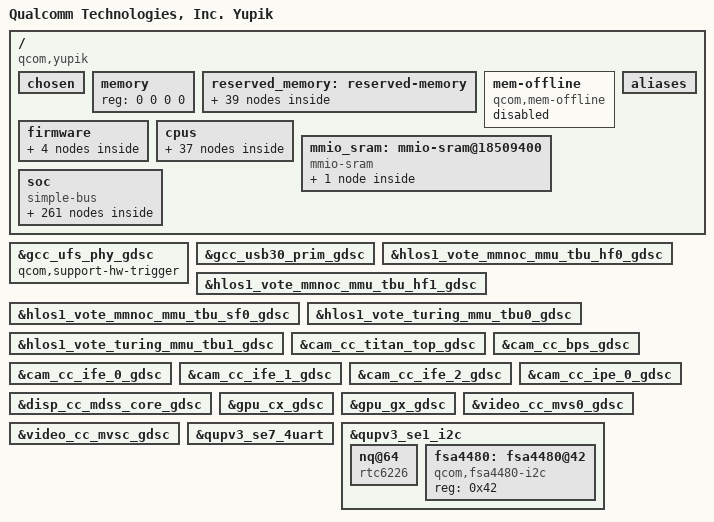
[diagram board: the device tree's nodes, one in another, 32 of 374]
// SPDX-License-Identifier: BSD-3-Clause
/*
 * Copyright (c) Qualcomm Technologies, Inc. and/or its subsidiaries.
 */

#include <dt-bindings/clock/qcom,aop-qmp.h>
#include <dt-bindings/clock/qcom,camcc-sc7280.h>
#include <dt-bindings/clock/qcom,dispcc-sc7280.h>
#include <dt-bindings/clock/qcom,gcc-sc7280.h>
#include <dt-bindings/clock/qcom,gpucc-sc7280.h>
#include <dt-bindings/clock/qcom,rpmh.h>
#include <dt-bindings/clock/qcom,videocc-sc7280.h>
#include <dt-bindings/interconnect/qcom,icc.h>
#include <dt-bindings/interconnect/qcom,yupik.h>
#include <dt-bindings/interrupt-controller/arm-gic.h>
#include <dt-bindings/soc/qcom,ipcc.h>
#include <dt-bindings/soc/qcom,dcc_v2.h>
#include <dt-bindings/soc/qcom,rpmh-rsc.h>
#include <dt-bindings/spmi/spmi.h>
#include <dt-bindings/gpio/gpio.h>
#include <dt-bindings/regulator/qcom,rpmh-regulator-levels.h>

/ {
	model = "Qualcomm Technologies, Inc. Yupik";
	compatible = "qcom,yupik";
	qcom,msm-id = <475 0x10000>, <515 0x10000>;
	interrupt-parent = <&intc>;

	#address-cells = <2>;
	#size-cells = <2>;

	chosen: chosen {
		bootargs = "loglevel=6 log_buf_len=512K earlycon=qcom_geni,0x994000 rcupdate.rcu_expedited=1  printk.console_no_auto_verbose=1 rcu_nocbs=0-7 kpti=0 cpufreq.default_governor=performance printk.devkmsg=on pcie_ports=compat fw_devlink.strict=1 android_arch_task_struct_size=512 androidboot.usbcontroller=a600000.dwc3";
		stdout-path = "/soc/qcom,qupv3_0_geni_se@9c0000/qcom,qup_uart@994000:115200n8";
	};

	memory { device_type = "memory"; reg = <0 0 0 0>; };

	reserved_memory: reserved-memory { };

	mem-offline {
		compatible = "qcom,mem-offline";
		offline-sizes = <0x1 0x40000000 0x0 0x40000000>,
			<0x1 0xc0000000 0x0 0x80000000>,
			<0x2 0xc0000000 0x1 0x40000000>;
		granule = <512>;
		mboxes = <&qmp_aop 0>;
		status = "disabled";
	};

	aliases: aliases {
		ufshc1 = &ufshc_mem; /* Embedded UFS Slot */
		mmc0 = &sdhc_1; /*SDC1 eMMC slot*/
		mmc1 = &sdhc_2; /* SDC2 SD card slot */
		serial0 = &qupv3_se5_2uart;
		hsuart0 = &qupv3_se7_4uart;
	};

	firmware: firmware {
		qcom_scm: qcom_scm { };
	};

	cpus {
		#address-cells = <2>;
		#size-cells = <0>;

		CPU0: cpu@0 {
			device_type = "cpu";
			compatible = "qcom,kryo";
			reg = <0x0 0x0>;
			enable-method = "psci";
			cpu-idle-states = <&LITTLE_CPU_SLEEP_0 &LITTLE_CPU_SLEEP_1>;
			power-domains = <&CPU_PD0>;
			power-domain-names = "psci";
			capacity-dmips-mhz = <1024>;
			dynamic-power-coefficient = <100>;
			qcom,freq-domain = <&cpufreq_hw 0 4>;
			next-level-cache = <&L2_0>;
			#cooling-cells = <2>;
			L2_0: l2-cache {
			      compatible = "cache";
			      cache-level = <2>;
			      next-level-cache = <&L3_0>;

				L3_0: l3-cache {
				      compatible = "cache";
				      cache-level = <3>;
				};
			};
		};

		CPU1: cpu@100 {
			device_type = "cpu";
			compatible = "qcom,kryo";
			reg = <0x0 0x100>;
			enable-method = "psci";
			cpu-idle-states = <&LITTLE_CPU_SLEEP_0 &LITTLE_CPU_SLEEP_1>;
			power-domains = <&CPU_PD1>;
			power-domain-names = "psci";
			capacity-dmips-mhz = <1024>;
			dynamic-power-coefficient = <100>;
			qcom,freq-domain = <&cpufreq_hw 0 4>;
			next-level-cache = <&L2_1>;
			#cooling-cells = <2>;
			L2_1: l2-cache {
			      compatible = "cache";
			      cache-level = <2>;
			      next-level-cache = <&L3_0>;
			};
		};

		CPU2: cpu@200 {
			device_type = "cpu";
			compatible = "qcom,kryo";
			reg = <0x0 0x200>;
			enable-method = "psci";
			cpu-idle-states = <&LITTLE_CPU_SLEEP_0 &LITTLE_CPU_SLEEP_1>;
			power-domains = <&CPU_PD2>;
			power-domain-names = "psci";
			capacity-dmips-mhz = <1024>;
			dynamic-power-coefficient = <100>;
			qcom,freq-domain = <&cpufreq_hw 0 4>;
			next-level-cache = <&L2_2>;
			#cooling-cells = <2>;
			L2_2: l2-cache {
			      compatible = "cache";
			      cache-level = <2>;
			      next-level-cache = <&L3_0>;
			};
		};

		CPU3: cpu@300 {
			device_type = "cpu";
			compatible = "qcom,kryo";
			reg = <0x0 0x300>;
			enable-method = "psci";
			cpu-idle-states = <&LITTLE_CPU_SLEEP_0 &LITTLE_CPU_SLEEP_1>;
			power-domains = <&CPU_PD3>;
			power-domain-names = "psci";
			capacity-dmips-mhz = <1024>;
			dynamic-power-coefficient = <100>;
			qcom,freq-domain = <&cpufreq_hw 0 4>;
			next-level-cache = <&L2_3>;
			#cooling-cells = <2>;
			L2_3: l2-cache {
			      compatible = "cache";
			      cache-level = <2>;
			      next-level-cache = <&L3_0>;
			};
		};

		CPU4: cpu@400 {
			device_type = "cpu";
			compatible = "qcom,kryo";
			reg = <0x0 0x400>;
			enable-method = "psci";
			cpu-idle-states = <&BIG_CPU_SLEEP_0 &BIG_CPU_SLEEP_1>;
			power-domains = <&CPU_PD4>;
			power-domain-names = "psci";
			capacity-dmips-mhz = <1946>;
			dynamic-power-coefficient = <520>;
			qcom,freq-domain = <&cpufreq_hw 1 4>;
			next-level-cache = <&L2_4>;
			#cooling-cells = <2>;
			L2_4: l2-cache {
			      compatible = "cache";
			      cache-level = <2>;
			      next-level-cache = <&L3_0>;
			};
		};

		CPU5: cpu@500 {
			device_type = "cpu";
			compatible = "qcom,kryo";
			reg = <0x0 0x500>;
			enable-method = "psci";
			cpu-idle-states = <&BIG_CPU_SLEEP_0 &BIG_CPU_SLEEP_1>;
			power-domains = <&CPU_PD5>;
			power-domain-names = "psci";
			capacity-dmips-mhz = <1946>;
			dynamic-power-coefficient = <520>;
			qcom,freq-domain = <&cpufreq_hw 1 4>;
			next-level-cache = <&L2_5>;
			#cooling-cells = <2>;
			L2_5: l2-cache {
			      compatible = "cache";
			      cache-level = <2>;
			      next-level-cache = <&L3_0>;
			};
		};

		CPU6: cpu@600 {
			device_type = "cpu";
			compatible = "qcom,kryo";
			reg = <0x0 0x600>;
			enable-method = "psci";
			cpu-idle-states = <&BIG_CPU_SLEEP_0 &BIG_CPU_SLEEP_1>;
			power-domains = <&CPU_PD6>;
			power-domain-names = "psci";
			capacity-dmips-mhz = <1946>;
			dynamic-power-coefficient = <520>;
			qcom,freq-domain = <&cpufreq_hw 1 4>;
			next-level-cache = <&L2_6>;
			#cooling-cells = <2>;
			L2_6: l2-cache {
			      compatible = "cache";
			      cache-level = <2>;
			      next-level-cache = <&L3_0>;
			};
		};

		CPU7: cpu@700 {
			device_type = "cpu";
			compatible = "qcom,kryo";
			reg = <0x0 0x700>;
			enable-method = "psci";
			cpu-idle-states = <&BIG_CPU_SLEEP_0 &BIG_CPU_SLEEP_1>;
			power-domains = <&CPU_PD7>;
			power-domain-names = "psci";
			capacity-dmips-mhz = <1985>;
			dynamic-power-coefficient = <552>;
			qcom,freq-domain = <&cpufreq_hw 2 4>;
			next-level-cache = <&L2_7>;
			#cooling-cells = <2>;
			L2_7: l2-cache {
			      compatible = "cache";
			      cache-level = <2>;
			      next-level-cache = <&L3_0>;
			};
		};

		cpu-map {
			cluster0 {
				core0 {
					cpu = <&CPU0>;
				};

				core1 {
					cpu = <&CPU1>;
				};

				core2 {
					cpu = <&CPU2>;
				};

				core3 {
					cpu = <&CPU3>;
				};
			};

			cluster1 {
				core0 {
					cpu = <&CPU4>;
				};

				core1 {
					cpu = <&CPU5>;
				};

				core2 {
					cpu = <&CPU6>;
				};
			};

			cluster2 {

				core0 {
					cpu = <&CPU7>;
				};
			};
		};

		idle-states {
			entry-method = "psci";

			LITTLE_CPU_SLEEP_0: cpu-sleep-0-0 {
				compatible = "arm,idle-state";
				idle-state-name = "little-power-down";
				arm,psci-suspend-param = <0x40000003>;
				entry-latency-us = <549>;
				exit-latency-us = <901>;
				min-residency-us = <1774>;
				local-timer-stop;
			};

			LITTLE_CPU_SLEEP_1: cpu-sleep-0-1 {
				compatible = "arm,idle-state";
				idle-state-name = "little-rail-power-down";
				arm,psci-suspend-param = <0x40000004>;
				entry-latency-us = <702>;
				exit-latency-us = <915>;
				min-residency-us = <4001>;
				local-timer-stop;
			};

			BIG_CPU_SLEEP_0: cpu-sleep-1-0 {
				compatible = "arm,idle-state";
				idle-state-name = "big-power-down";
				arm,psci-suspend-param = <0x40000003>;
				entry-latency-us = <523>;
				exit-latency-us = <1244>;
				min-residency-us = <2207>;
				local-timer-stop;
			};

			BIG_CPU_SLEEP_1: cpu-sleep-1-1 {
				compatible = "arm,idle-state";
				idle-state-name = "big-rail-power-down";
				arm,psci-suspend-param = <0x40000004>;
				entry-latency-us = <526>;
				exit-latency-us = <1854>;
				min-residency-us = <5555>;
				local-timer-stop;
			};

			CLUSTER_SLEEP_APSS_OFF: cluster-sleep-0 {
				compatible = "domain-idle-state";
				arm,psci-suspend-param = <0x41000044>;
				entry-latency-us = <2752>;
				exit-latency-us = <3048>;
				min-residency-us = <6118>;
			};

			CLUSTER_SLEEP_CX_RET: cluster-sleep-1 {
				compatible = "domain-idle-state";
				arm,psci-suspend-param = <0x41001344>;
				entry-latency-us = <3263>;
				exit-latency-us = <4562>;
				min-residency-us = <8467>;
			};

			CLUSTER_SLEEP_LLCC_OFF: cluster-sleep-2 {
				compatible = "domain-idle-state";
				arm,psci-suspend-param = <0x4100b344>;
				entry-latency-us = <3638>;
				exit-latency-us = <6562>;
				min-residency-us = <9826>;
			};
		};
	};

	mmio_sram: mmio-sram@18509400 {
		#address-cells = <2>;
		#size-cells = <2>;
		compatible = "mmio-sram";
		no-memory-wc;
		reg = <0x0 0x18509400 0x0 0x400>;
		ranges = <0x0 0x0 0x0 0x18509400 0x0 0x400>;

		cpu_scp_lpri: scp-shmem@0 {
			compatible = "arm,scp-shmem";
			reg = <0x0 0x0 0x0 0x80>;
		};
	};

	soc: soc { };

};

&firmware {
	qcom_scm {
		compatible = "qcom,scm";
		qcom,dload-mode = <&tcsr 0x13000>;
	};

	qcom_smcinvoke {
		compatible = "qcom,smcinvoke";
	};

	qcom_mem_object {
		compatible = "qcom,mem-object";
	};

	qtee_shmbridge {
		compatible = "qcom,tee-shared-memory-bridge";
	};
};

&reserved_memory {
	#address-cells = <2>;
	#size-cells = <2>;
	ranges;

	hyp_mem: hyp@80000000 {
		no-map;
		reg = <0x0 0x80000000 0x0 0x600000>;
	};

	xbl_aop_mem: xbl_aop_mem@80700000 {
		no-map;
		reg = <0x0 0x80700000 0x0 0x160000>;
	};

	cmd_db: cmd_db@80860000 {
		compatible = "qcom,cmd-db";
		no-map;
		reg = <0x0 0x80860000 0x0 0x20000>;
	};

	reserved_xbl_uefi: reserved_xbl_uefi@80880000 {
		no-map;
		reg = <0x0 0x80880000 0x0 0x14000>;
	};

	secdata_apss_mem: secdata_apss@808ff000 {
		no-map;
		reg = <0x0 0x808ff000 0x0 0x1000>;
	};

	smem_mem: smem@80900000 {
		no-map;
		reg = <0x0 0x80900000 0x0 0x200000>;
	};

	fw_mem: fw@80b00000 {
		no-map;
		reg = <0x0 0x80b00000 0x0 0x100000>;
	};

	wlan_fw_mem: wlan_fw@80c00000 {
		no-map;
		reg = <0x0 0x80c00000 0x0 0xc00000>;
	};

	cdsp_secure_heap_mem: cdsp_secure_heap@81800000 {
		no-map;
		reg = <0x0 0x81800000 0x0 0x1e00000>;
	};

	pil_cvp_mem: camera@86200000 {
		no-map;
		reg = <0x0 0x86200000 0x0 0x500000>;
	};

	pil_adsp_mem: adsp@86700000 {
		no-map;
		reg = <0x0 0x86700000 0x0 0x2800000>;
	};

	pil_cdsp_mem: cdsp@88f00000 {
		no-map;
		reg = <0x0 0x88f00000 0x0 0x1e00000>;
	};

	adsp_mem: adsp_region {
		compatible = "shared-dma-pool";
		alloc-ranges = <0x0 0x00000000 0x0 0xffffffff>;
		reusable;
		alignment = <0x0 0x400000>;
		size = <0x0 0xC00000>;
	};

	pil_camera_mem: video@8ad00000 {
		no-map;
		reg = <0x0 0x8ad00000 0x0 0x500000>;
	};

	pil_ipa_fw_mem: ipa_fw@8b700000 {
		no-map;
		reg = <0x0 0x8b700000 0x0 0x10000>;
	};

	pil_ipa_gsi_mem: ipa_gsi@8b710000 {
		no-map;
		reg = <0x0 0x8b710000 0x0 0xa000>;
	};

	pil_gpu_micro_code_mem: gpu_micro_code@8b71a000 {
		no-map;
		reg = <0x0 0x8b71a000 0x0 0x2000>;
	};

	pil_mpss_mem: mpss@8b800000 {
		no-map;
		reg = <0x0 0x8b800000 0x0 0xf600000>;
	};

	pil_wpss_mem: wlan@9ae00000 {
		no-map;
		reg = <0x0 0x9ae00000 0x0 0x1900000>;
	};

	removed_mem: removed_region@c0000000 {
		no-map;
		reg = <0x0 0xc0000000 0x0 0x5100000>;
	};

	pil_trustedvm_mem: pil_trustedvm_region@d0800000 {
		no-map;
		reg = <0x0 0xd0800000 0x0 0x76f7000>;
	};

	qrtr_shbuf: qrtr-shmem {
		no-map;
		reg = <0x0 0xd7ef7000 0x0 0x9000>;
	};

	chan0_shbuf: neuron_block@0 {
		no-map;
		reg = <0x0 0xd7f00000 0x0 0x80000>;
	};

	chan1_shbuf: neuron_block@1 {
		no-map;
		reg = <0x0 0xd7f80000 0x0 0x80000>;
	};

	video_mem: video_region@85b00000 {
		no-map;
		reg = <0x0 0x85b00000 0x0 0x700000>;
	};

	user_contig_mem: user_contig_region {
		compatible = "shared-dma-pool";
		alloc-ranges = <0x0 0x00000000 0x0 0xffffffff>;
		reusable;
		alignment = <0x0 0x400000>;
		size = <0x0 0x1000000>;
	};

	qseecom_mem: qseecom_region {
		compatible = "shared-dma-pool";
		alloc-ranges = <0x0 0x00000000 0x0 0xffffffff>;
		reusable;
		alignment = <0x0 0x400000>;
		size = <0x0 0x1400000>;
	};

	non_secure_display_memory: non_secure_display_region {
		compatible = "shared-dma-pool";
		alloc-ranges = <0x0 0x00000000 0x0 0xffffffff>;
		reusable;
		alignment = <0x0 0x400000>;
		size = <0x0 0x6400000>;
	};

	splash_memory:splash_region {
		reg = <0x0 0xe1000000 0x0 0x02400000>;
		label = "cont_splash_region";
	};

	qseecom_ta_mem: qseecom_ta_region {
		compatible = "shared-dma-pool";
		alloc-ranges = <0x0 0x00000000 0x0 0xffffffff>;
		reusable;
		alignment = <0x0 0x400000>;
		size = <0x0 0x1000000>;
	};

	secure_display_memory: secure_display_region {
		compatible = "shared-dma-pool";
		alloc-ranges = <0 0x00000000 0 0xffffffff>;
		reusable;
		alignment = <0 0x400000>;
		size = <0 0x8c00000>;
	};

	ramoops_mem: ramoops-region {
		alloc-ranges = <0x1 0x00000000 0xfffffffe 0xffffffff>;
		size = <0x0 0x200000>;
		no-map;
	};

	/* global autoconfigured region for contiguous allocations */
	system_cma: linux,cma {
		compatible = "shared-dma-pool";
		alloc-ranges = <0x0 0x00000000 0x0 0xffffffff>;
		reusable;
		alignment = <0x0 0x400000>;
		size = <0x0 0x2000000>;
		linux,cma-default;
	};

	kinfo_mem: debug_kinfo_region {
		alloc-ranges = <0x0 0x00000000 0xffffffff 0xffffffff>;
		size = <0x0 0x1000>;
		no-map;
	};

	va_md_mem: va_md_mem_region {
		compatible = "shared-dma-pool";
		alloc-ranges = <0x0 0x00000000 0x0 0xffffffff>;
		reusable;
		size = <0 0x1000000>;
	};

	audio_cma_mem: audio_cma_region {
		compatible = "shared-dma-pool";
		alloc-ranges = <0x0 0x00000000 0x0 0xffffffff>;
		reusable;
		alignment = <0x0 0x400000>;
		size = <0x0 0x1C00000>;
	};

	splash_memory:splash_region {
		reg = <0x0 0xe1000000 0x0 0x02300000>;
		label = "cont_splash_region";
	};

	dfps_data_memory: dfps_data_memory {
		reg = <0x0 0xe3300000 0x0 0x0100000>;
		label = "dfps_data_memory";
	};

	memshare_mem: memshare_region {
		compatible = "shared-dma-pool";
		no-map;
		/*
		 * Memory shared with modem needs to be outside of
		 * the CLADE address space, which begins at
		 * 0xE0000000 and spans 512 MB.
		 */
		alloc-ranges = <0x0 0x00000000 0x0 0xdfffffff>;
		alignment = <0x0 0x100000>;
		size = <0x0 0x800000>;
	};

	cnss_wlan_mem: cnss_wlan_region {
		compatible = "shared-dma-pool";
		alloc-ranges = <0x0 0x00000000 0x0 0xffffffff>;
		reusable;
		alignment = <0x0 0x400000>;
		size = <0x0 0x1400000>;
	};

};

&soc {
	#address-cells = <1>;
	#size-cells = <1>;
	ranges = <0 0 0 0xffffffff>;
	compatible = "simple-bus";

	slimbam: dma-controller@3a84000 {
		compatible = "qcom,bam-v1.7.0";
		reg = <0x03a84000 0x20000>;
		interrupts = <GIC_SPI 164 IRQ_TYPE_LEVEL_HIGH>;
		#dma-cells = <1>;
		qcom,controlled-remotely;
		num-channels = <31>;
		qcom,ee = <1>;
		qcom,num-ees = <2>;
		iommus = <&apps_smmu 0x1826 0x0>;
	};

	slim_msm: slim@3ac0000 {
		compatible = "qcom,slim-ngd-v1.5.0";
		reg = <0x03ac0000 0x2c000>;
		interrupts = <GIC_SPI 163 IRQ_TYPE_LEVEL_HIGH>;
		dmas = <&slimbam 3>, <&slimbam 4>;
		dma-names = "rx", "tx";
		iommus = <&apps_smmu 0x1826 0x0>;
		qcom,wait_for_adsp_up;
		#address-cells = <1>;
		#size-cells = <0>;
		status = "disabled";
	};

	intc: interrupt-controller@17a00000 {
		compatible = "arm,gic-v3";
		#interrupt-cells = <3>;
		interrupt-controller;
		#redistributor-regions = <1>;
		redistributor-stride = <0x0 0x20000>;
		reg = <0x17a00000 0x10000>,     /* GICD */
		      <0x17a60000 0x100000>;    /* GICR * 8 */
		interrupts = <GIC_PPI 9 IRQ_TYPE_LEVEL_HIGH>;
	};

	pdc: interrupt-controller@b220000 {
		compatible = "qcom,yupik-pdc", "qcom,pdc";
		reg = <0xb220000 0x10000>, <0x17c000f0 0x60>;
		qcom,pdc-ranges = <0 480 40>, <40 140 14>, <54 263 1>,
				  <55 306 4>, <59 312 3>, <62 374 2>,
				  <64 434 2>, <66 438 3>, <69 86 1>,
				  <70 520 54>, <124 609 31>, <155 63 1>,
				  <156 716 12>;
		#interrupt-cells = <2>;
		interrupt-parent = <&intc>;
		interrupt-controller;
	};

	wdog: qcom,wdt@17c10000 {
		compatible = "qcom,msm-watchdog";
		reg = <0x17c10000 0x1000>;
		reg-names = "wdt-base";
		interrupts = <GIC_SPI 0 IRQ_TYPE_LEVEL_HIGH>;
	};

	psci {
		compatible = "arm,psci-1.0";
		method = "smc";

		CPU_PD0: power-domain-cpu0 {
			#power-domain-cells = <0>;
			power-domains = <&CLUSTER_PD>;
		};

		CPU_PD1: power-domain-cpu1 {
			#power-domain-cells = <0>;
			power-domains = <&CLUSTER_PD>;
		};

		CPU_PD2: power-domain-cpu2 {
			#power-domain-cells = <0>;
			Power-domains = <&CLUSTER_PD>;
		};

		CPU_PD3: power-domain-cpu3 {
			#power-domain-cells = <0>;
			power-domains = <&CLUSTER_PD>;
		};

		CPU_PD4: power-domain-cpu4 {
			#power-domain-cells = <0>;
			power-domains = <&CLUSTER_PD>;
		};

		CPU_PD5: power-domain-cpu5 {
			#power-domain-cells = <0>;
			power-domains = <&CLUSTER_PD>;
		};

		CPU_PD6: power-domain-cpu6 {
			#power-domain-cells = <0>;
			power-domains = <&CLUSTER_PD>;
		};

		CPU_PD7: power-domain-cpu7 {
			#power-domain-cells = <0>;
			power-domains = <&CLUSTER_PD>;
		};

		CLUSTER_PD: power-domain-cluster {
			#power-domain-cells = <0>;
			domain-idle-states = <&CLUSTER_SLEEP_APSS_OFF &CLUSTER_SLEEP_CX_RET &CLUSTER_SLEEP_LLCC_OFF>;
		};
	};

	qcom_tzlog: tz-log@0x146aa720 {
		compatible = "qcom,tz-log";
		reg = <0x146aa720 0x3000>;
		qcom,hyplog-enabled;
		hyplog-address-offset = <0x410>;
		hyplog-size-offset = <0x414>;
	};

	qcom_qseecom: qseecom@c1800000 {
		compatible = "qcom,qseecom";
		memory-region = <&qseecom_mem>;
		qcom,hlos-num-ce-hw-instances = <1>;
		qcom,hlos-ce-hw-instance = <0>;
		qcom,qsee-ce-hw-instance = <0>;
		qcom,disk-encrypt-pipe-pair = <2>;
		qcom,support-fde;
		qcom,no-clock-support;
		qcom,fde-key-size;
		qcom,appsbl-qseecom-support;
		qcom,commonlib64-loaded-by-uefi;
		qcom,qsee-reentrancy-support = <2>;
	};

	qcom_cedev: qcedev@1de0000 {
		compatible = "qcom,qcedev";
		reg = <0x1de0000 0x20000>,
			<0x1dc4000 0x24000>;
		reg-names = "crypto-base","crypto-bam-base";
		interrupts = <GIC_SPI 272 IRQ_TYPE_LEVEL_HIGH>;
		qcom,bam-pipe-pair = <3>;
		qcom,ce-hw-instance = <0>;
		qcom,ce-device = <0>;
		qcom,ce-hw-shared;
		qcom,bam-ee = <0>;
		qcom,smmu-s1-enable;
		qcom,no-clock-support;
		interconnect-names = "data_path";
		interconnects = <&aggre2_noc MASTER_CRYPTO &mc_virt SLAVE_EBI1>;
		iommus = <&apps_smmu 0x04E6 0x0011>;
		qcom,iommu-dma = "atomic";

		qcom_cedev_ns_cb {
			compatible = "qcom,qcedev,context-bank";
			label = "ns_context";
			iommus = <&apps_smmu 0x4F2 0>,
				 <&apps_smmu 0x4F8 0>,
				 <&apps_smmu 0x4F9 0>,
				 <&apps_smmu 0x4FF 0>;
		};

		qcom_cedev_s_cb {
			compatible = "qcom,qcedev,context-bank";
			label = "secure_context";
			iommus = <&apps_smmu 0x4F3 0>,
				 <&apps_smmu 0x4FC 0>,
				 <&apps_smmu 0x4FD 0>,
				 <&apps_smmu 0x4FE 0>;
			qcom,iommu-vmid = <0x9>; /* VMID_CP_BITSTREAM */
			qcom,secure-context-bank;
		};
	};

	rng: rng@10d3000 {
		compatible = "qcom,trng";
		reg = <0x10d3000 0x1000>;
	};

	qcom_crypto: qcrypto@1de0000 {
		reg = <0x1de0000 0x20000>,
			 <0x1dc4000 0x24000>;
		reg-names = "crypto-base","crypto-bam-base";
		interrupts = <GIC_SPI 272 IRQ_TYPE_LEVEL_HIGH>;
		qcom,bam-pipe-pair = <2>;
		qcom,ce-hw-instance = <0>;
		qcom,ce-device = <0>;
		qcom,bam-ee = <0>;
		qcom,ce-hw-shared;
		qcom,clk-mgmt-sus-res;
		qcom,use-sw-aes-cbc-ecb-ctr-algo;
		qcom,use-sw-aes-xts-algo;
		qcom,use-sw-aes-ccm-algo;
		qcom,use-sw-ahash-algo;
		qcom,use-sw-aead-algo;
		qcom,use-sw-hmac-algo;
		qcom,smmu-s1-enable;
		qcom,no-clock-support;
		interconnect-names = "data_path";
		interconnects = <&aggre2_noc MASTER_CRYPTO &mc_virt SLAVE_EBI1>;
		iommus = <&apps_smmu 0x04E4 0x0011>;
		qcom,iommu-dma = "atomic";
	};

	ipcc_mproc: qcom,ipcc@408000 {
		compatible = "qcom,ipcc";
		reg = <0x408000 0x1000>;
		interrupts = <GIC_SPI 229 IRQ_TYPE_LEVEL_HIGH>;
		interrupt-controller;
		#interrupt-cells = <3>;
		#mbox-cells = <2>;
	};


	arch_timer: timer {
		compatible = "arm,armv8-timer";
		interrupts = <GIC_PPI 13 (GIC_CPU_MASK_SIMPLE(8) | IRQ_TYPE_LEVEL_LOW)>,
			     <GIC_PPI 14 (GIC_CPU_MASK_SIMPLE(8) | IRQ_TYPE_LEVEL_LOW)>,
			     <GIC_PPI 11 (GIC_CPU_MASK_SIMPLE(8) | IRQ_TYPE_LEVEL_LOW)>,
			     <GIC_PPI 12 (GIC_CPU_MASK_SIMPLE(8) | IRQ_TYPE_LEVEL_LOW)>;
		clock-frequency = <19200000>;
	};

	memtimer: timer@17c20000 {
		#address-cells = <1>;
		#size-cells = <1>;
		ranges;
		compatible = "arm,armv7-timer-mem";
		reg = <0x17c20000 0x1000>;
		clock-frequency = <19200000>;

		frame@17c21000 {
			frame-number = <0>;
			interrupts = <GIC_SPI 8 IRQ_TYPE_LEVEL_HIGH>,
				     <GIC_SPI 6 IRQ_TYPE_LEVEL_HIGH>;
			reg = <0x17c21000 0x1000>,
			      <0x17c22000 0x1000>;
		};

		frame@17c23000 {
			frame-number = <1>;
			interrupts = <GIC_SPI 9 IRQ_TYPE_LEVEL_HIGH>;
			reg = <0x17c23000 0x1000>;
			status = "disabled";
		};

		frame@17c25000 {
			frame-number = <2>;
			interrupts = <GIC_SPI 10 IRQ_TYPE_LEVEL_HIGH>;
			reg = <0x17c25000 0x1000>;
			status = "disabled";
		};

		frame@17c27000 {
			frame-number = <3>;
			interrupts = <GIC_SPI 11 IRQ_TYPE_LEVEL_HIGH>;
			reg = <0x17c27000 0x1000>;
			status = "disabled";
		};

		frame@17c29000 {
			frame-number = <4>;
			interrupts = <GIC_SPI 12 IRQ_TYPE_LEVEL_HIGH>;
			reg = <0x17c29000 0x1000>;
			status = "disabled";
		};

		frame@17c2b000 {
			frame-number = <5>;
			interrupts = <GIC_SPI 13 IRQ_TYPE_LEVEL_HIGH>;
			reg = <0x17c2b000 0x1000>;
			status = "disabled";
		};

		frame@17c2d000 {
			frame-number = <6>;
			interrupts = <GIC_SPI 14 IRQ_TYPE_LEVEL_HIGH>;
			reg = <0x17c2d000 0x1000>;
			status = "disabled";
		};
	};


	qcom,msm-imem@146aa000 {
		compatible = "qcom,msm-imem";
		reg = <0x146aa000 0x1000>;
		ranges = <0x0 0x146aa000 0x1000>;
		#address-cells = <1>;
		#size-cells = <1>;

		mem_dump_table@10 {
			compatible = "qcom,msm-imem-mem_dump_table";
			reg = <0x10 0x8>;
		};

		restart_reason@65c {
			compatible = "qcom,msm-imem-restart_reason";
			reg = <0x65c 0x4>;
		};

		dload_type@1c {
			compatible = "qcom,msm-imem-dload-type";
			reg = <0x1c 0x4>;
		};

		boot_stats@6b0 {
			compatible = "qcom,msm-imem-boot_stats";
			reg = <0x6b0 0x20>;
		};

		kaslr_offset@6d0 {
			compatible = "qcom,msm-imem-kaslr_offset";
			reg = <0x6d0 0xc>;
		};

		pil@94c {
			compatible = "qcom,pil-reloc-info";
			reg = <0x94c 0xc8>;
		};

		pil@6dc {
			compatible = "qcom,msm-imem-pil-disable-timeout";
			reg = <0x6dc 0x4>;
		};

		diag_dload@c8 {
			compatible = "qcom,msm-imem-diag-dload";
			reg = <0xc8 0xc8>;
		};
	};

	eud: qcom,msm-eud@88e0000 {
		compatible = "qcom,msm-eud";
		interrupt-names = "eud_irq";
		interrupt-parent = <&pdc>;
		interrupts = <11 IRQ_TYPE_LEVEL_HIGH>;
		reg = <0x088e0000 0x2000>,
			<0x088e2000 0x1000>;
		reg-names = "eud_base", "eud_mode_mgr2";
		qcom,secure-eud-en;
		status = "ok";
	};

	qcom,memshare {
		compatible = "qcom,memshare";

		qcom,client_1 {
			compatible = "qcom,memshare-peripheral";
			qcom,peripheral-size = <0x0>;
			qcom,client-id = <0>;
			qcom,allocate-boot-time;
			label = "modem";
		};

		qcom,client_2 {
			compatible = "qcom,memshare-peripheral";
			qcom,peripheral-size = <0x0>;
			qcom,client-id = <2>;
			label = "modem";
		};

		qcom,client_3 {
			compatible = "qcom,memshare-peripheral";
			qcom,peripheral-size = <0x500000>;
			memory-region = <&memshare_mem>;
			qcom,client-id = <1>;
			qcom,allocate-on-request;
			label = "modem";
		};
	};

	clocks {
		xo_board: xo-board {
			compatible = "fixed-clock";
			clock-frequency = <76800000>;
			clock-output-names = "xo_board";
			#clock-cells = <0>;
		};

		sleep_clk: sleep-clk {
			compatible = "fixed-clock";
			clock-frequency = <32000>;
			clock-output-names = "sleep_clk";
			#clock-cells = <0>;
		};

		pcie_0_pipe_clk: pcie-0-pipe-clk {
			compatible = "fixed-clock";
			clock-frequency = <1000>;
			clock-output-names = "pcie_0_pipe_clk";
			#clock-cells = <0>;
		};

		pcie_1_pipe_clk: pcie-1-pipe-clk {
			compatible = "fixed-clock";
			clock-frequency = <1000>;
			clock-output-names = "pcie_1_pipe_clk";
			#clock-cells = <0>;
		};

		usb3_phy_wrapper_gcc_usb30_pipe_clk: usb3-phy-wrapper-gcc-usb30-pipe-clk {
			compatible = "fixed-clock";
			clock-frequency = <1000>;
			clock-output-names = "usb3_phy_wrapper_gcc_usb30_pipe_clk";
			#clock-cells = <0>;
		};
	};

	gcc: clock-controller@100000 {
		compatible = "qcom,gcc-sc7280", "syscon";
		reg = <0x100000 0x1f0000>;
		reg-names = "cc_base";
		vdd_cx-supply = <&VDD_CX_LEVEL>;
		clocks = <&rpmhcc RPMH_CXO_CLK>,
			<&sleep_clk>,
			<&usb3_phy_wrapper_gcc_usb30_pipe_clk>;
		clock-names = "bi_tcxo",
			"sleep_clk",
			"usb3_phy_wrapper_gcc_usb30_pipe_clk";

		protected-clocks = <GCC_AGGRE_NOC_PCIE_0_AXI_CLK>,
		<GCC_AGGRE_NOC_PCIE_1_AXI_CLK>, <GCC_DDRSS_PCIE_SF_CLK>,
		<GCC_PCIE0_PHY_RCHNG_CLK>, <GCC_PCIE1_PHY_RCHNG_CLK>,
		<GCC_PCIE_0_AUX_CLK>, <GCC_PCIE_0_AUX_CLK_SRC>,
		<GCC_PCIE_0_CFG_AHB_CLK>, <GCC_PCIE_0_MSTR_AXI_CLK>,
		<GCC_PCIE_0_PHY_RCHNG_CLK_SRC>, <GCC_PCIE_0_PIPE_CLK>,
		<GCC_PCIE_0_PIPE_CLK_SRC>, <GCC_PCIE_0_SLV_AXI_CLK>,
		<GCC_PCIE_0_SLV_Q2A_AXI_CLK>, <GCC_PCIE_1_AUX_CLK>,
		<GCC_PCIE_1_AUX_CLK_SRC>, <GCC_PCIE_1_CFG_AHB_CLK>,
		<GCC_PCIE_1_MSTR_AXI_CLK>, <GCC_PCIE_1_PHY_RCHNG_CLK_SRC>,
		<GCC_PCIE_1_PIPE_CLK>, <GCC_PCIE_1_PIPE_CLK_SRC>,
		<GCC_PCIE_1_SLV_AXI_CLK>, <GCC_PCIE_1_SLV_Q2A_AXI_CLK>,
		<GCC_PCIE_THROTTLE_CORE_CLK>, <GCC_THROTTLE_PCIE_AHB_CLK>,
		<GCC_AGGRE_USB3_SEC_AXI_CLK>, <GCC_CFG_NOC_USB3_SEC_AXI_CLK>,
		<GCC_USB30_SEC_MASTER_CLK>, <GCC_USB30_SEC_MASTER_CLK_SRC>,
		<GCC_USB30_SEC_MOCK_UTMI_CLK>, <GCC_USB30_SEC_MOCK_UTMI_CLK_SRC>,
		<GCC_USB30_SEC_MOCK_UTMI_POSTDIV_CLK_SRC>, <GCC_USB30_SEC_SLEEP_CLK>,
		<GCC_USB3_SEC_PHY_AUX_CLK>, <GCC_USB3_SEC_PHY_AUX_CLK_SRC>,
		<GCC_USB3_SEC_PHY_COM_AUX_CLK>, <GCC_USB3_SEC_PHY_PIPE_CLK>,
		<GCC_USB3_SEC_PHY_PIPE_CLK_SRC>, <GCC_AGGRE_NOC_PCIE_CENTER_SF_AXI_CLK>,
		<GCC_AGGRE_NOC_PCIE_TBU_CLK>, <GCC_PCIE_CLKREF_EN>;

		#clock-cells = <1>;
		#reset-cells = <1>;
	};

	camcc: clock-controller@ad00000 {
		compatible = "qcom,sc7280-camcc", "syscon";
		reg = <0xad00000 0x10000>;
		reg-names = "cc_base";
		vdd_mx-supply = <&VDD_MX_LEVEL>;
		vdd_cx-supply = <&VDD_CX_LEVEL>;
		clocks = <&rpmhcc RPMH_CXO_CLK>, <&rpmhcc RPMH_CXO_CLK_A>,
			<&sleep_clk>, <&gcc GCC_CAMERA_AHB_CLK>;
		clock-names = "bi_tcxo", "bi_tcxo_ao", "sleep_clk", "cfg_ahb";
		#clock-cells = <1>;
		#reset-cells = <1>;
	};

	dispcc: clock-controller@af00000 {
		compatible = "qcom,sc7280-dispcc", "syscon";
		reg = <0xaf00000 0x20000>;
		reg-names = "cc_base";
		vdd_cx-supply = <&VDD_CX_LEVEL>;
		clocks = <&rpmhcc RPMH_CXO_CLK>, <&gcc GCC_DISP_GPLL0_CLK_SRC>,
		       <&gcc GCC_DISP_AHB_CLK>;
		clock-names = "bi_tcxo", "gcc_disp_gpll0_clk","cfg_ahb";
		#clock-cells = <1>;
		#reset-cells = <1>;
	};

	gpucc: clock-controller@3d90000 {
		compatible = "qcom,sc7280-gpucc", "syscon";
		reg = <0x3d90000 0x9000>;
		reg-names = "cc_base";
		vdd_cx-supply = <&VDD_CX_LEVEL>;
		vdd_mx-supply = <&VDD_MX_LEVEL>;
		clocks = <&rpmhcc RPMH_CXO_CLK>, <&gcc GCC_GPU_GPLL0_CLK_SRC>,
			<&gcc GCC_GPU_GPLL0_DIV_CLK_SRC>, <&gcc GCC_GPU_CFG_AHB_CLK>;
		clock-names = "bi_tcxo", "gcc_gpu_gpll0_clk_src",
			"gcc_gpu_gpll0_div_clk_src", "cfg_ahb";
		#clock-cells = <1>;
		#reset-cells = <1>;
	};

	videocc: clock-controller@aaf0000 {
		compatible = "qcom,sc7280-videocc", "syscon";
		reg = <0xaaf0000 0x10000>;
		reg-names = "cc_base";
		vdd_cx-supply = <&VDD_CX_LEVEL>;
		clocks = <&rpmhcc RPMH_CXO_CLK>, <&rpmhcc RPMH_CXO_CLK_A>,
			<&sleep_clk>, <&gcc GCC_VIDEO_AHB_CLK>;
		clock-names = "bi_tcxo", "bi_tcxo_ao", "sleep_clk", "cfg_ahb";
		#clock-cells = <1>;
		#reset-cells = <1>;
	};

	apsscc: syscon@182a0000 {
		compatible = "syscon";
		reg = <0x182a0000 0x1c>;
	};

	mccc: syscon@90ba000 {
		compatible = "syscon";
		reg = <0x90ba000 0x54>;
	};

	debugcc: debug-clock-controller@0 {
		compatible = "qcom,debugcc-sc7280";
		qcom,gcc = <&gcc>;
		qcom,camcc = <&camcc>;
		qcom,dispcc = <&dispcc>;
		qcom,gpucc = <&gpucc>;
		qcom,videocc = <&videocc>;
		qcom,apsscc = <&apsscc>;
		qcom,mccc = <&mccc>;
		clocks = <&rpmhcc RPMH_CXO_CLK>,
			 <&camcc 0>,
			 <&dispcc 0>,
			 <&gcc 0>,
			 <&gpucc 0>,
			 <&videocc 0>;
		clock-names = "xo_clk_src",
			      "camcc",
			      "dispcc",
			      "gcc",
			      "gpucc",
			      "videocc";
		#clock-cells = <1>;
	};

	cpufreq_hw: qcom,cpufreq-hw {
		compatible = "qcom,cpufreq-epss";
		reg = <0x18591000 0x1000>, <0x18592000 0x1000>,
			<0x18593000 0x1000>;
		reg-names = "freq-domain0", "freq-domain1",
				"freq-domain2";

		clocks = <&rpmhcc RPMH_CXO_CLK>, <&gcc GCC_GPLL0>;
		clock-names = "xo", "alternate";

		qcom,lut-row-size = <4>;
		qcom,skip-enable-check;

		interrupts = <GIC_SPI 30 IRQ_TYPE_LEVEL_HIGH>,
				<GIC_SPI 31 IRQ_TYPE_LEVEL_HIGH>,
				<GIC_SPI 19 IRQ_TYPE_LEVEL_HIGH>;
		interrupt-names = "dcvsh0_int", "dcvsh1_int", "dcvsh2_int";

		qcom,sdpm-cx-mx-1 = <0x00636f08 0x4>;
		qcom,sdpm-cx-mx-2 = <0x00636f0c 0x4>;

		#freq-domain-cells = <2>;
	};

	qcom,cpufreq-hw-debug@18591000 {
		compatible = "qcom,cpufreq-hw-epss-debug";
		reg = <0x18591000 0x800>;
		reg-names = "domain-top";
		qcom,freq-hw-domain = <&cpufreq_hw 0>, <&cpufreq_hw 1>,
					<&cpufreq_hw 2>;
	};

	qcom_hwkm: hwkm@10c0000 {
		compatible = "qcom,hwkm";
		reg = <0x10c0000 0x9000>, <0x1d90000 0x9000>;
		reg-names = "km_master", "ice_slave";
		qcom,enable-hwkm-clk;
		clock-names = "km_clk_src";
		clocks = <&rpmhcc RPMH_HWKM_CLK>;
		qcom,op-freq-hz = <75000000>;
	};

	ufsphy_mem: ufsphy_mem@1d87000 {
		reg = <0x1d87000 0xe00>;
		reg-names = "phy_mem";
		#phy-cells = <0>;

		lanes-per-direction = <2>;
		clock-names = "ref_clk_src",
			"ref_clk",
			"ref_aux_clk";
		clocks = <&rpmhcc RPMH_CXO_CLK>,
			<&gcc GCC_UFS_1_CLKREF_EN>,
			<&gcc GCC_UFS_PHY_PHY_AUX_CLK>;
		resets = <&ufshc_mem 0>;

		status = "disabled";
	};

	bluetooth: bt_wcn6750 {
		compatible = "qcom,wcn6750-bt";
		pinctrl-names = "default";
		pinctrl-0 = <&bt_en_sleep>;
		qcom,bt-reset-gpio = <&tlmm 85 0>; /* BT_EN */
		qcom,bt-sw-ctrl-gpio = <&tlmm 86 0>; /* SW_CTRL */
		qcom,wl-reset-gpio = <&tlmm 84 0>; /* WL_EN */

		qcom,bt-vdd-io-supply = <&L19B>;  /* IO */
		qcom,bt-vdd-aon-supply = <&S7B>;
		qcom,bt-vdd-dig-supply = <&S7B>;
		qcom,bt-vdd-rfacmn-supply = <&S7B>;
		qcom,bt-vdd-rfa-0p8-supply = <&S7B>;
		qcom,bt-vdd-rfa1-supply = <&S1B>; /*RFA 1p7*/
		qcom,bt-vdd-rfa2-supply = <&S8B>; /*RFA 1p2*/
		qcom,bt-vdd-ipa-2p2-supply = <&S1C>; /*IPA 2p2*/
		qcom,bt-vdd-asd-supply = <&L11C>;

		/* max voltage are set to regulator max voltage supported */
		qcom,bt-vdd-io-config = <1800000 2000000 0 1>;
		qcom,bt-vdd-aon-config = <824000 1120000 0 1>;
		qcom,bt-vdd-dig-config = <824000 1120000 0 1>;
		qcom,bt-vdd-rfacmn-config  = <824000 1120000 0 1>;
		qcom,bt-vdd-rfa-0p8-config  = <824000 1120000 0 1>;
		qcom,bt-vdd-rfa1-config = <1872000 2040000 0 1>;
		qcom,bt-vdd-rfa2-config = <1256000 1500000 0 1>;
		qcom,bt-vdd-ipa-2p2-config = <2200000 2210000 0 1>;
		qcom,bt-vdd-asd-config = <2800000 3544000 0 1>;
	};

	vendor_hooks: qcom,cpu-vendor-hooks {
		compatible = "qcom,cpu-vendor-hooks";
	};

	ufshc_mem: ufshc@1d84000 {
		compatible = "qcom,ufshc";
		reg = <0x1d84000 0x3000>,
		      <0x1d88000 0x8000>,
		      <0x1d90000 0x9000>;
		reg-names = "ufs_mem", "ufs_ice", "ufs_ice_hwkm";
		interrupts = <GIC_SPI 265 IRQ_TYPE_LEVEL_HIGH>;
		phys = <&ufsphy_mem>;
		phy-names = "ufsphy";
		#reset-cells = <1>;

		lanes-per-direction = <2>;
		dev-ref-clk-freq = <0>; /* 19.2 MHz */

		boot_device_type = <0x0>;
		nvmem-cells = <&boot_config>;
		nvmem-cell-names = "boot_conf";

		clock-names =
			"core_clk",
			"bus_aggr_clk",
			"iface_clk",
			"core_clk_unipro",
			"core_clk_ice",
			"ref_clk",
			"tx_lane0_sync_clk",
			"rx_lane0_sync_clk",
			"rx_lane1_sync_clk";
		clocks =
			<&gcc GCC_UFS_PHY_AXI_CLK>,
			<&gcc GCC_AGGRE_UFS_PHY_AXI_CLK>,
			<&gcc GCC_UFS_PHY_AHB_CLK>,
			<&gcc GCC_UFS_PHY_UNIPRO_CORE_CLK>,
			<&gcc GCC_UFS_PHY_ICE_CORE_CLK>,
			<&rpmhcc RPMH_CXO_CLK>,
			<&gcc GCC_UFS_PHY_TX_SYMBOL_0_CLK>,
			<&gcc GCC_UFS_PHY_RX_SYMBOL_0_CLK>,
			<&gcc GCC_UFS_PHY_RX_SYMBOL_1_CLK>;
		freq-table-hz =
			<75000000 300000000>,
			<0 0>,
			<0 0>,
			<75000000 300000000>,
			<75000000 300000000>,
			<0 0>,
			<0 0>,
			<0 0>,
			<0 0>;

		interconnects = <&aggre1_noc MASTER_UFS_MEM &mc_virt SLAVE_EBI1>,
			<&gem_noc MASTER_APPSS_PROC &cnoc2 SLAVE_UFS_MEM_CFG>;
		interconnect-names = "ufs-ddr", "cpu-ufs";

		qcom,ufs-bus-bw,name = "ufshc_mem";
		qcom,ufs-bus-bw,num-cases = <26>;
		qcom,ufs-bus-bw,num-paths = <2>;
		qcom,ufs-bus-bw,vectors-KBps =
		/*
		 * During HS G3 UFS runs at nominal voltage corner, vote
		 * higher bandwidth to push other buses in the data path
		 * to run at nominal to achieve max throughput.
		 * 4GBps pushes BIMC to run at nominal.
		 * 200MBps pushes CNOC to run at nominal.
		 * Vote for half of this bandwidth for HS G3 1-lane.
		 * For max bandwidth, vote high enough to push the buses
		 * to run in turbo voltage corner.
		 */
		<0 0>, <0 0>,          /* No vote */
		<922 0>, <1000 0>,     /* PWM G1 */
		<1844 0>, <1000 0>,    /* PWM G2 */
		<3688 0>, <1000 0>,    /* PWM G3 */
		<7376 0>, <1000 0>,    /* PWM G4 */
		<1844 0>, <1000 0>,    /* PWM G1 L2 */
		<3688 0>, <1000 0>,    /* PWM G2 L2 */
		<7376 0>, <1000 0>,    /* PWM G3 L2 */
		<14752 0>, <1000 0>,   /* PWM G4 L2 */
		<127796 0>, <1000 0>,  /* HS G1 RA */
		<255591 0>, <1000 0>,  /* HS G2 RA */
		<2097152 0>, <102400 0>,  /* HS G3 RA */
		<4194304 0>, <204800 0>,  /* HS G4 RA */
		<255591 0>, <1000 0>,  /* HS G1 RA L2 */
		<511181 0>, <1000 0>,  /* HS G2 RA L2 */
		<4194304 0>, <204800 0>, /* HS G3 RA L2 */
		<8388608 0>, <409600 0>, /* HS G4 RA L2 */
		<149422 0>, <1000 0>,  /* HS G1 RB */
		<298189 0>, <1000 0>,  /* HS G2 RB */
		<2097152 0>, <102400 0>,  /* HS G3 RB */
		<4194304 0>, <204800 0>,  /* HS G4 RB */
		<298189 0>, <1000 0>,  /* HS G1 RB L2 */
		<596378 0>, <1000 0>,  /* HS G2 RB L2 */
		/* As UFS working in HS G3 RB L2 mode, aggregated
		 * bandwidth (AB) should take care of providing
		 * optimum throughput requested. However, as tested,
		 * in order to scale up CNOC clock, instantaneous
		 * bindwidth (IB) needs to be given a proper value too.
		 */
		<4194304 0>, <204800 409600>, /* HS G3 RB L2 */
		<8388608 0>, <409600 409600>, /* HS G4 RB L2 */
		<7643136 0>, <307200 0>; /* Max. bandwidth */

		qcom,bus-vector-names = "MIN",
		"PWM_G1_L1", "PWM_G2_L1", "PWM_G3_L1", "PWM_G4_L1",
		"PWM_G1_L2", "PWM_G2_L2", "PWM_G3_L2", "PWM_G4_L2",
		"HS_RA_G1_L1", "HS_RA_G2_L1", "HS_RA_G3_L1", "HS_RA_G4_L1",
		"HS_RA_G1_L2", "HS_RA_G2_L2", "HS_RA_G3_L2", "HS_RA_G4_L2",
		"HS_RB_G1_L1", "HS_RB_G2_L1", "HS_RB_G3_L1", "HS_RB_G4_L1",
		"HS_RB_G1_L2", "HS_RB_G2_L2", "HS_RB_G3_L2", "HS_RB_G4_L2",
		"MAX";

		reset-gpios = <&tlmm 175 GPIO_ACTIVE_LOW>;
		resets = <&gcc GCC_UFS_PHY_BCR>;
		reset-names = "rst";

		depends-on-supply = <&apps_smmu>;
		iommus = <&apps_smmu 0x80 0x0>;
		qcom,iommu-dma = "fastmap";

		dma-coherent;

		/*
		 * UFS2.2 is drawing 40mA current during APPS PC.
		 * Issue is seen only if PX10 is turned off and Vccq2 is ON.
		 * Since Vccq2 is always-on supply we can't turn it off,
		 * so don't turn off PX10, by updating spm_lvl to 3.
		 * In sleep state (spm-lvl=3) its drawing only .5mA.
		 */
		spm-level = <3>;

		status = "disabled";

		qos0 {
			mask = <0xf0>;
			vote = <65>;
			perf;
		};

		qos1 {
			mask = <0x0f>;
			vote = <59>;
		};
	};

	cpu_pmu: cpu-pmu {
		compatible = "arm,armv8-pmuv3";
		qcom,irq-is-percpu;
		interrupts = <GIC_PPI 7 IRQ_TYPE_LEVEL_LOW>;
	};

	google,debug-kinfo {
		compatible = "google,debug-kinfo";
		memory-region = <&kinfo_mem>;
	};

	mini_dump_mode {
		compatible = "qcom,minidump";
		status = "ok";
	};

	va_mini_dump {
		compatible = "qcom,va-minidump";
		memory-region = <&va_md_mem>;
		status = "ok";
	};

	logbuf: qcom,logbuf-vendor-hooks {
		compatible = "qcom,logbuf-vendor-hooks";
	};

	kryo-erp {
		compatible = "arm,arm64-kryo-cpu-erp";
		interrupts = <GIC_PPI 0 IRQ_TYPE_LEVEL_HIGH>,
			<GIC_SPI 35 IRQ_TYPE_LEVEL_HIGH>;
		interrupt-names = "l1-l2-faultirq","l3-scu-faultirq";
	};

	qcom,mpm2-sleep-counter@c221000 {
		compatible = "qcom,mpm2-sleep-counter";
		reg = <0xc221000 0x1000>;
		clock-frequency = <32768>;
	};

	cache-controller@9200000 {
		compatible = "qcom,yupik-llcc","qcom,llcc-v2";
		reg = <0x9200000 0x58000>, <0x9280000 0x58000>, <0x9600000 0x58000>;
		reg-names = "llcc0_base", "llcc1_base", "llcc_broadcast_base";
		interrupts = <GIC_SPI 266 IRQ_TYPE_LEVEL_HIGH>;
		cap-based-alloc-and-pwr-collapse;

		llcc_perfmon {
			compatible = "qcom,llcc-perfmon";
			clocks = <&aoss_qmp QDSS_CLK>;
			clock-names = "qdss_clk";
		};
	};

	clk_virt: interconnect {
		compatible = "qcom,yupik-clk_virt";
		#interconnect-cells = <1>;
		qcom,bcm-voter-names = "hlos";
		qcom,bcm-voters = <&apps_bcm_voter>;
	};

	cnoc2: interconnect@1500000 {
		reg = <0x1500000 0x1000>;
		compatible = "qcom,yupik-cnoc2";
		#interconnect-cells = <1>;
		qcom,bcm-voter-names = "hlos";
		qcom,bcm-voters = <&apps_bcm_voter>;
	};

	cnoc3: interconnect@1502000 {
		reg = <0x1502000 0x1000>;
		compatible = "qcom,yupik-cnoc3";
		#interconnect-cells = <1>;
		qcom,bcm-voter-names = "hlos";
		qcom,bcm-voters = <&apps_bcm_voter>;
	};

	mc_virt: interconnect@1580000 {
		reg = <0x1580000 0x4>;
		compatible = "qcom,yupik-mc_virt";
		#interconnect-cells = <1>;
		qcom,bcm-voter-names = "hlos", "disp";
		qcom,bcm-voters = <&apps_bcm_voter>, <&disp_bcm_voter>;
	};

	system_noc: interconnect@1680000 {
		reg = <0x1680000 0x15480>;
		compatible = "qcom,yupik-system_noc";
		#interconnect-cells = <1>;
		qcom,bcm-voter-names = "hlos";
		qcom,bcm-voters = <&apps_bcm_voter>;
	};

	aggre1_noc: interconnect@16e0000 {
		compatible = "qcom,yupik-aggre1_noc";
		reg = <0x016e0000 0x1c080>;
		#interconnect-cells = <1>;
		qcom,bcm-voter-names = "hlos";
		qcom,bcm-voters = <&apps_bcm_voter>;
		clocks = <&gcc GCC_AGGRE_UFS_PHY_AXI_CLK>,
			<&gcc GCC_AGGRE_USB3_PRIM_AXI_CLK>;
	};

	aggre2_noc: interconnect@1700000 {
		reg = <0x1700000 0x2b080>;
		compatible = "qcom,yupik-aggre2_noc";
		#interconnect-cells = <1>;
		qcom,bcm-voter-names = "hlos";
		qcom,bcm-voters = <&apps_bcm_voter>;
		clocks = <&rpmhcc RPMH_IPA_CLK>;
	};

	mmss_noc: interconnect@1740000 {
		reg = <0x1740000 0x1e080>;
		compatible = "qcom,yupik-mmss_noc";
		#interconnect-cells = <1>;
		qcom,bcm-voter-names = "hlos", "disp";
		qcom,bcm-voters = <&apps_bcm_voter>, <&disp_bcm_voter>;
	};

	lpass_ag_noc: interconnect@3c40000 {
		reg = <0x03c40000 0xf080>;
		compatible = "qcom,yupik-lpass_ag_noc";
		#interconnect-cells = <1>;
		qcom,bcm-voter-names = "hlos";
		qcom,bcm-voters = <&apps_bcm_voter>;
	};

	dc_noc: interconnect@90e0000 {
		reg = <0x90e0000 0x5080>;
		compatible = "qcom,yupik-dc_noc";
		#interconnect-cells = <1>;
		qcom,bcm-voter-names = "hlos";
		qcom,bcm-voters = <&apps_bcm_voter>;
	};

	gem_noc: interconnect@9100000 {
		reg = <0x9100000 0xe2200>;
		compatible = "qcom,yupik-gem_noc";
		#interconnect-cells = <1>;
		qcom,bcm-voter-names = "hlos", "disp";
		qcom,bcm-voters = <&apps_bcm_voter>, <&disp_bcm_voter>;
	};

	nsp_noc: interconnect@a0c0000 {
		reg = <0x0a0c0000 0x10000>;
		compatible = "qcom,yupik-nsp_noc";
		#interconnect-cells = <1>;
		qcom,bcm-voter-names = "hlos";
		qcom,bcm-voters = <&apps_bcm_voter>;
	};

	llcc_pmu: llcc-pmu@9095000 {
		compatible = "qcom,llcc-pmu-ver2";
		reg = <0x09095000 0x300>;
		reg-names = "lagg-base";
	};

	qcom_pmu: qcom,pmu {
		compatible = "qcom,pmu";
		qcom,long-counter;
		qcom,pmu-events-tbl =
			< 0x0008 0xFF 0xFF 0xFF >,
			< 0x0011 0xFF 0xFF 0xFF >,
			< 0x0017 0xFF 0xFF 0xFF >,
			< 0x002A 0xFF 0xFF 0xFF >,
			< 0x1000 0xFF 0xFF 0xFF >;
	};

	llcc_freq_table: llcc-freq-table {
		qcom,freq-tbl =
			< 150000 >,
			< 300000 >,
			< 466000 >,
			< 600000 >,
			< 806000 >,
			< 933000 >,
			< 1066000 >;
	};

	ddr_freq_table: ddr-freq-table {
		qcom,freq-tbl =
			<  200000 >,
			<  451000 >,
			<  547000 >,
			<  681000 >,
			<  768000 >,
			< 1017000 >,
			< 1353000 >,
			< 1555000 >,
			< 1708000 >,
			< 2092000 >,
			< 2133000 >,
			< 2736000 >,
			< 3196000 >;
	};

	ddrqos_freq_table: ddrqos-freq-table {
		qcom,freq-tbl =
			< 0 >,
			< 1 >;
	};

	qcom_dcvs: qcom,dcvs {
		compatible = "qcom,dcvs";
		#address-cells = <1>;
		#size-cells = <1>;
		ranges;

		qcom_ddr_dcvs_hw: ddr {
			compatible = "qcom,dcvs-hw";
			qcom,dcvs-hw-type = <0>;
			qcom,bus-width = <4>;
			qcom,freq-tbl = <&ddr_freq_table>;

			ddr_dcvs_sp: sp {
				compatible = "qcom,dcvs-path";
				qcom,dcvs-path-type = <0>;
				interconnects = <&mc_virt MASTER_LLCC
						 &mc_virt SLAVE_EBI1>;
			};
		};

		qcom_llcc_dcvs_hw: llcc {
			compatible = "qcom,dcvs-hw";
			qcom,dcvs-hw-type = <1>;
			qcom,bus-width = <16>;
			qcom,freq-tbl = <&llcc_freq_table>;

			llcc_dcvs_sp: sp {
				compatible = "qcom,dcvs-path";
				qcom,dcvs-path-type = <0>;
				interconnects = <&gem_noc MASTER_APPSS_PROC
						 &gem_noc SLAVE_LLCC>;
			};
		};

		qcom_l3_dcvs_hw: l3 {
			compatible = "qcom,dcvs-hw";
			qcom,dcvs-hw-type = <2>;
			qcom,bus-width = <32>;
			qcom,ftbl-row-size = <0x20>;
			reg = <0x18590000 0x4000>, <0x18590100 0xa0>;
			reg-names = "l3-base", "l3tbl-base";

			l3_dcvs_sp: sp {
				compatible = "qcom,dcvs-path";
				qcom,dcvs-path-type = <0>;
				qcom,shared-offset = <0x0920>;
			};
		};

		qcom_ddrqos_dcvs_hw: ddrqos {
			compatible = "qcom,dcvs-hw";
			qcom,dcvs-hw-type = <3>;
			qcom,bus-width = <1>;
			qcom,freq-tbl = <&ddrqos_freq_table>;

			ddrqos_dcvs_sp: sp {
				compatible = "qcom,dcvs-path";
				qcom,dcvs-path-type = <0>;
				interconnects = <&mc_virt MASTER_LLCC
						 &mc_virt SLAVE_EBI1>;
			};
		};
	 };

	qcom_memlat: qcom,memlat {
		compatible = "qcom,memlat";

		ddr {
			compatible = "qcom,memlat-grp";
			qcom,target-dev = <&qcom_ddr_dcvs_hw>;
			qcom,sampling-path = <&ddr_dcvs_sp>;
			qcom,miss-ev = <0x1000>;

			silver {
				compatible = "qcom,memlat-mon";
				qcom,cpulist = <&CPU0 &CPU1 &CPU2 &CPU3>;
				qcom,sampling-enabled;
				ddr4-tbl {
					qcom,ddr-type = <7>;
					qcom,cpufreq-memfreq-tbl =
						<  940800  451000 >,
						< 1152000  547000 >,
						< 1516800  768000 >,
						< 1804800 1017000 >;
				};

				ddr5-tbl {
					qcom,ddr-type = <8>;
					qcom,cpufreq-memfreq-tbl =
						<  940800  451000 >,
						< 1152000  547000 >,
						< 1516800  768000 >,
						< 1804800 1555000 >;
				};
			};

			gold {
				compatible = "qcom,memlat-mon";
				qcom,cpulist = <&CPU4 &CPU5 &CPU6 &CPU7>;
				qcom,sampling-enabled;
				ddr4-tbl {
					qcom,ddr-type = <7>;
					qcom,cpufreq-memfreq-tbl =
						<  691200  451000 >,
						<  940800  547000 >,
						< 1228800 1017000 >,
						< 1651200 1555000 >,
						< 2380800 1708000 >,
						< 2707200 2133000 >;
				};

				ddr5-tbl {
					qcom,ddr-type = <8>;
					qcom,cpufreq-memfreq-tbl =
						<  691200  451000 >,
						<  940800  547000 >,
						< 1228800  768000 >,
						< 1651200 1555000 >,
						< 1900800 1708000 >,
						< 2380800 2092000 >,
						< 2707200 3196000 >;
				};
			};

			silver-compute {
				compatible = "qcom,memlat-mon";
				qcom,cpulist = <&CPU0 &CPU1 &CPU2 &CPU3>;
				qcom,cpufreq-memfreq-tbl =
					< 1152000 451000 >,
					< 1516800 547000 >,
					< 1804800 768000 >;
				qcom,sampling-enabled;
				qcom,compute-mon;
			};

			gold-compute {
				compatible = "qcom,memlat-mon";
				qcom,cpulist = <&CPU4 &CPU5 &CPU6>;
				qcom,sampling-enabled;
				qcom,compute-mon;
				ddr4-tbl {
					qcom,ddr-type = <7>;
					qcom,cpufreq-memfreq-tbl =
						<  691200  451000 >,
						< 1228800  547000 >,
						< 1516800  768000 >,
						< 1651200 1017000 >,
						< 1900800 1555000 >,
						< 2400000 1708000 >,
						< 2707200 2133000 >;
				};

				ddr5-tbl {
					qcom,ddr-type = <8>;
					qcom,cpufreq-memfreq-tbl =
						<  691200  451000 >,
						< 1228800  547000 >,
						< 1516800  768000 >,
						< 1651200 1555000 >,
						< 1900800 1708000 >,
						< 2400000 2092000 >,
						< 2707200 3196000 >;
				};
			};

			prime-compute {
				compatible = "qcom,memlat-mon";
				qcom,cpulist = <&CPU7>;
				qcom,sampling-enabled;
				qcom,compute-mon;

				ddr4-tbl {
					qcom,ddr-type = <7>;
					qcom,cpufreq-memfreq-tbl =
						< 2380800  451000 >,
						< 2707200 2133000 >;
				};

				ddr5-tbl {
					qcom,ddr-type = <8>;
					qcom,cpufreq-memfreq-tbl =
						< 2380800  451000 >,
						< 2707200 3196000 >;
				};
			};
		};

		llcc {
			compatible = "qcom,memlat-grp";
			qcom,target-dev = <&qcom_llcc_dcvs_hw>;
			qcom,sampling-path = <&llcc_dcvs_sp>;
			qcom,miss-ev = <0x2A>;

			silver {
				compatible = "qcom,memlat-mon";
				qcom,cpulist = <&CPU0 &CPU1 &CPU2 &CPU3>;
				qcom,cpufreq-memfreq-tbl =
					< 1152000 300000 >,
					< 1516800 466000 >,
					< 1804800 600000 >;
				qcom,sampling-enabled;
			};

			gold {
				compatible = "qcom,memlat-mon";
				qcom,cpulist = <&CPU4 &CPU5 &CPU6 &CPU7>;
				qcom,cpufreq-memfreq-tbl =
					<  691200   300000 >,
					<  940800   466000 >,
					< 1228800   600000 >,
					< 1651200   806000 >,
					< 2400000   933000 >,
					< 2707200  1066000 >;
				qcom,sampling-enabled;
			};

			gold-compute {
				compatible = "qcom,memlat-mon";
				qcom,cpulist = <&CPU4 &CPU5 &CPU6 &CPU7>;
				qcom,cpufreq-memfreq-tbl =
					< 1900800  150000 >,
					< 2707200  600000 >;
				qcom,sampling-enabled;
				qcom,compute-mon;
			};
		};

		l3 {
			compatible = "qcom,memlat-grp";
			qcom,target-dev = <&qcom_l3_dcvs_hw>;
			qcom,sampling-path = <&l3_dcvs_sp>;
			qcom,miss-ev = <0x17>;

			prime-compute {
				compatible = "qcom,memlat-mon";
				qcom,cpulist = <&CPU7>;
				qcom,cpufreq-memfreq-tbl =
					< 2035200  300000000 >,
					< 2707200 1516800000 >;
				qcom,sampling-enabled;
				qcom,compute-mon;
			};
		};

		ddrqos {
			compatible = "qcom,memlat-grp";
			qcom,target-dev = <&qcom_ddrqos_dcvs_hw>;
			qcom,sampling-path = <&ddrqos_dcvs_sp>;
			qcom,miss-ev = <0x1000>;

			ddrqos_gold_lat: gold {
				compatible = "qcom,memlat-mon";
				qcom,cpulist = <&CPU4 &CPU5 &CPU6 &CPU7>;
				qcom,cpufreq-memfreq-tbl =
					<  300000 1 >,
					< 3000000 2 >;
				qcom,sampling-enabled;
			};

			ddrqos_prime_lat: prime {
				compatible = "qcom,memlat-mon";
				qcom,cpulist = <&CPU7>;
				qcom,cpufreq-memfreq-tbl =
					< 2035200 1 >,
					< 2707200 2 >;
				qcom,sampling-enabled;
			};
		};
	};

	bwmon_llcc: qcom,bwmon-llcc@90b6400 {
		compatible = "qcom,bwmon4";
		reg = <0x90b6400 0x300>, <0x90b6300 0x200>;
		reg-names = "base", "global_base";
		interrupts = <GIC_SPI 581 IRQ_TYPE_LEVEL_HIGH>;
		qcom,mport = <0>;
		qcom,hw-timer-hz = <19200000>;
		qcom,target-dev = <&qcom_llcc_dcvs_hw>;
		qcom,count-unit = <0x10000>;
	};

	bwmon_ddr: qcom,bwmon-ddr@9091000 {
		compatible = "qcom,bwmon5";
		reg = <0x9091000 0x1000>;
		reg-names = "base";
		interrupts = <GIC_SPI 81 IRQ_TYPE_LEVEL_HIGH>;
		qcom,hw-timer-hz = <19200000>;
		qcom,target-dev = <&qcom_ddr_dcvs_hw>;
		qcom,count-unit = <0x10000>;
	};

	bwmon_l3: qcom,bwmon-l3@90b9100 {
		compatible = "qcom,bwmon4";
		reg = <0x90b9100 0x300>, <0x90b9000 0x200>;
		reg-names = "base", "global_base";
		interrupts = <GIC_SPI 226 IRQ_TYPE_LEVEL_HIGH>;
		qcom,mport = <0>;
		qcom,hw-timer-hz = <19200000>;
		qcom,target-dev = <&qcom_l3_dcvs_hw>;
		qcom,count-unit = <0x10000>;
	};

	msm_gpu: qcom,kgsl-3d0@3d00000 {
		#cooling-cells = <2>;
	};

	cpucp: qcom,cpucp@17C00000 {
		compatible = "qcom,cpucp";
		reg =   <0x17C00000 0x10>,
			<0x18590000 0x2000>;
		reg-names = "tx", "rx";
		#mbox-cells = <1>;
		interrupts = <0 62 4>;
	};

	scmi: qcom,scmi {
		#address-cells = <1>;
		#size-cells = <0>;
		compatible = "arm,scmi";
		mboxes = <&cpucp 0>;
		mbox-names = "tx";
		shmem = <&cpu_scp_lpri>;

		scmi_memlat: protocol@80 {
			reg = <0x80>;
			#clock-cells = <1>;
		};

		scmi_perf_lock: protocol@81 {
			reg = <0x81>;
			#clock-cells = <1>;
		};
	};

	cpucp_log: qcom,cpucp_log@18509C00 {
		compatible = "qcom,cpucp-log";
		reg = <0x18509C00 0x200>,
			<0x18509E00 0x200>;
		mboxes = <&cpucp 1>;
	};

	apps_rsc: rsc@18200000 {
		label = "apps_rsc";
		compatible = "qcom,rpmh-rsc";
		reg = <0x18200000 0x10000>,
		      <0x18210000 0x10000>,
		      <0x18220000 0x10000>;
		reg-names = "drv-0", "drv-1", "drv-2";
		interrupts = <GIC_SPI 3 IRQ_TYPE_LEVEL_HIGH>,
			     <GIC_SPI 4 IRQ_TYPE_LEVEL_HIGH>,
			     <GIC_SPI 5 IRQ_TYPE_LEVEL_HIGH>;
		qcom,drv-count = <3>;
		power-domains = <&CLUSTER_PD>;

		apps_rsc_drv2: drv@2 {
			qcom,tcs-offset = <0xd00>;
			qcom,drv-id = <2>;
			channel@0 {
				qcom,tcs-config = <ACTIVE_TCS  2>,
						<SLEEP_TCS   3>,
						<WAKE_TCS    3>,
						<CONTROL_TCS 0>,
						<FAST_PATH_TCS 0>;
			};

			apps_bcm_voter: bcm_voter {
				compatible = "qcom,bcm-voter";
			};

			rpmhcc: qcom,rpmhclk {
				compatible = "qcom,sc7280-rpmh-clk";
				#clock-cells = <1>;
			};
		};
	};

	disp_rsc: rsc@af20000 {
		label = "disp_rsc";
		compatible = "qcom,rpmh-rsc";
		reg = <0xaf20000 0x10000>;
		reg-names = "drv-0";
		interrupts = <GIC_SPI 129 IRQ_TYPE_LEVEL_HIGH>;
		qcom,drv-count = <1>;

		disp_rsc_drv0: drv@0 {
			qcom,tcs-offset = <0x1c00>;
			qcom,drv-id = <0>;
			channel@0 {
				qcom,tcs-config = <ACTIVE_TCS  0>,
					  <SLEEP_TCS   1>,
					  <WAKE_TCS    1>,
					  <CONTROL_TCS 0>,
					  <FAST_PATH_TCS 0>;
			};

			disp_bcm_voter: bcm_voter {
				compatible = "qcom,bcm-voter";
				qcom,tcs-wait = <QCOM_ICC_TAG_AMC>;
			};
		};
	};

	sram@c3f0000 {
		compatible = "qcom,rpmh-stats";
		reg = <0x0c3f0000 0x400>;
		ss-name = "modem", "adsp", "adsp_island",
			  "cdsp", "apss";
	};

	cluster-device {
		compatible = "qcom,lpm-cluster-dev";
		power-domains = <&CLUSTER_PD>;
	};

	spmi_bus: qcom,spmi@c440000 {
		compatible = "qcom,spmi-pmic-arb";
		reg = <0xc440000 0x1100>,
		      <0xc600000 0x2000000>,
		      <0xe600000 0x100000>,
		      <0xe700000 0xa0000>,
		      <0xc40a000 0x26000>;
		reg-names = "core", "chnls", "obsrvr", "intr", "cnfg";
		interrupts-extended = <&pdc 1 IRQ_TYPE_LEVEL_HIGH>;
		interrupt-names = "periph_irq";
		interrupt-controller;
		#interrupt-cells = <4>;
		#address-cells = <2>;
		#size-cells = <0>;
		cell-index = <0>;
		qcom,channel = <0>;
		qcom,ee = <0>;
	};

	spmi_debug_bus: qcom,spmi-debug@6b12000 {
		compatible = "qcom,spmi-pmic-arb-debug";
		reg = <0x6b12000 0x60>, <0x7820b0 0x4>;
		reg-names = "core", "fuse";
		clocks = <&aoss_qmp QDSS_CLK>;
		clock-names = "core_clk";
		qcom,fuse-disable-bit = <24>;
		#address-cells = <2>;
		#size-cells = <0>;
		status = "disabled";

		qcom,pmk8350-debug@0 {
			compatible = "qcom,spmi-pmic";
			reg = <0 SPMI_USID>;
			#address-cells = <2>;
			#size-cells = <0>;
			qcom,can-sleep;
		};

		qcom,pm7325-debug@1 {
			compatible = "qcom,spmi-pmic";
			reg = <1 SPMI_USID>;
			#address-cells = <2>;
			#size-cells = <0>;
			qcom,can-sleep;
		};

		qcom,pm8350c-debug@2 {
			compatible = "qcom,spmi-pmic";
			reg = <2 SPMI_USID>;
			#address-cells = <2>;
			#size-cells = <0>;
			qcom,can-sleep;
		};

		qcom,pm8350b-debug@3 {
			compatible = "qcom,spmi-pmic";
			reg = <3 SPMI_USID>;
			#address-cells = <2>;
			#size-cells = <0>;
			qcom,can-sleep;
		};

		qcom,pmr735a-debug@5 {
			compatible = "qcom,spmi-pmic";
			reg = <4 SPMI_USID>;
			#address-cells = <2>;
			#size-cells = <0>;
			qcom,can-sleep;
		};
	};

	qcom,pmic_glink {
		compatible = "qcom,qti-pmic-glink";
		qcom,pmic-glink-channel = "PMIC_RTR_ADSP_APPS";
		qcom,subsys-name = "adsp";
		qcom,protection-domain = "tms/servreg", "msm/adsp/charger_pd";

		battery_charger: qcom,battery_charger {
			compatible = "qcom,battery-charger";
		};

		ucsi: qcom,ucsi {
			compatible = "qcom,ucsi-glink";
		};

		altmode: qcom,altmode {
			compatible = "qcom,altmode-glink";
			#altmode-cells = <1>;
		};
	};

	qcom,pmic_glink_log {
		compatible = "qcom,qti-pmic-glink";
		qcom,pmic-glink-channel = "PMIC_LOGS_ADSP_APPS";

		qcom,battery_debug {
			compatible = "qcom,battery-debug";
		};

		spmi_glink_debug: qcom,spmi_glink_debug {
			compatible = "qcom,spmi-glink-debug";
			#address-cells = <1>;
			#size-cells = <0>;
			status = "disabled";

			/* Primary SPMI bus */
			spmi@0 {
				reg = <0>;
				#address-cells = <2>;
				#size-cells = <0>;

				qcom,pm8350b-debug@3 {
					compatible = "qcom,spmi-pmic";
					reg = <3 SPMI_USID>;
					qcom,can-sleep;
				};
			};

			/* Secondary (QUP) SPMI bus */
			spmi@1 {
				reg = <1>;
				#address-cells = <2>;
				#size-cells = <0>;

				qcom,smb1394-debug@b {
					compatible = "qcom,spmi-pmic";
					reg = <11 SPMI_USID>;
					qcom,can-sleep;
				};

				qcom,smb1394-debug@c {
					compatible = "qcom,spmi-pmic";
					reg = <12 SPMI_USID>;
					qcom,can-sleep;
				};

			};
		};
	};

	thermal_zones: thermal-zones {
	};

	qmi_tmd: qmi-tmd-devices {
		compatible = "qcom,qmi-cooling-devices";
	};

	tcsr_mutex_block: syscon@1f40000 {
		compatible = "syscon";
		reg = <0x1f40000 0x20000>;
	};

	tcsr_mutex: hwlock {
		compatible = "qcom,tcsr-mutex";
		syscon = <&tcsr_mutex_block 0 0x1000>;
		#hwlock-cells = <1>;
	};

	tcsr: syscon@1fc0000 {
		compatible = "syscon";
		reg = <0x1fc0000 0x30000>;
	};

	smem: qcom,smem {
		compatible = "qcom,smem";
		memory-region = <&smem_mem>;
		hwlocks = <&tcsr_mutex 3>;
	};

	qcom,smp2p-adsp {
		compatible = "qcom,smp2p";
		qcom,smem = <443>, <429>;
		interrupt-parent = <&ipcc_mproc>;
		interrupts = <IPCC_CLIENT_LPASS IPCC_MPROC_SIGNAL_SMP2P
			      IRQ_TYPE_EDGE_RISING>;
		mboxes = <&ipcc_mproc IPCC_CLIENT_LPASS
			  IPCC_MPROC_SIGNAL_SMP2P>;
		qcom,local-pid = <0>;
		qcom,remote-pid = <2>;

		adsp_smp2p_out: master-kernel {
			qcom,entry-name = "master-kernel";
			#qcom,smem-state-cells = <1>;
		};

		adsp_smp2p_in: slave-kernel {
			qcom,entry-name = "slave-kernel";
			interrupt-controller;
			#interrupt-cells = <2>;
		};

		smp2p_rdbg2_out: qcom,smp2p-rdbg2-out {
			qcom,entry-name = "rdbg";
			#qcom,smem-state-cells = <1>;
		};

		smp2p_rdbg2_in: qcom,smp2p-rdbg2-in {
			qcom,entry-name = "rdbg";
			interrupt-controller;
			#interrupt-cells = <2>;
		};

		sleepstate_smp2p_out: sleepstate-out {
			qcom,entry-name = "sleepstate";
			#qcom,smem-state-cells = <1>;
		};

		sleepstate_smp2p_in: qcom,sleepstate-in {
			qcom,entry-name = "sleepstate_see";
			interrupt-controller;
			#interrupt-cells = <2>;
		};
	};

	qcom,smp2p_sleepstate {
		compatible = "qcom,smp2p-sleepstate";
		qcom,smem-states = <&sleepstate_smp2p_out 0>;
		interrupt-parent = <&sleepstate_smp2p_in>;
		interrupts = <0 0>;
		interrupt-names = "smp2p-sleepstate-in";
	};

	qcom,smp2p-nsp {
		compatible = "qcom,smp2p";
		qcom,smem = <94>, <432>;
		interrupt-parent = <&ipcc_mproc>;
		interrupts = <IPCC_CLIENT_CDSP IPCC_MPROC_SIGNAL_SMP2P
			      IRQ_TYPE_EDGE_RISING>;
		mboxes = <&ipcc_mproc IPCC_CLIENT_CDSP IPCC_MPROC_SIGNAL_SMP2P>;
		qcom,local-pid = <0>;
		qcom,remote-pid = <5>;

		cdsp_smp2p_out: master-kernel {
			qcom,entry-name = "master-kernel";
			#qcom,smem-state-cells = <1>;
		};

		cdsp_smp2p_in: slave-kernel {
			qcom,entry-name = "slave-kernel";
			interrupt-controller;
			#interrupt-cells = <2>;
		};

		smp2p_rdbg5_out: qcom,smp2p-rdbg5-out {
			qcom,entry-name = "rdbg";
			#qcom,smem-state-cells = <1>;
		};

		smp2p_rdbg5_in: qcom,smp2p-rdbg5-in {
			qcom,entry-name = "rdbg";
			interrupt-controller;
			#interrupt-cells = <2>;
		};
	};

	qcom,smp2p-modem {
		compatible = "qcom,smp2p";
		qcom,smem = <435>, <428>;
		interrupt-parent = <&ipcc_mproc>;
		interrupts = <IPCC_CLIENT_MPSS IPCC_MPROC_SIGNAL_SMP2P
			      IRQ_TYPE_EDGE_RISING>;
		mboxes = <&ipcc_mproc IPCC_CLIENT_MPSS IPCC_MPROC_SIGNAL_SMP2P>;
		qcom,local-pid = <0>;
		qcom,remote-pid = <1>;

		modem_smp2p_out: master-kernel {
			qcom,entry-name = "master-kernel";
			#qcom,smem-state-cells = <1>;
		};

		modem_smp2p_in: slave-kernel {
			qcom,entry-name = "slave-kernel";
			interrupt-controller;
			#interrupt-cells = <2>;
		};

		smp2p_ipa_1_out: qcom,smp2p-ipa-1-out {
			qcom,entry-name = "ipa";
			#qcom,smem-state-cells = <1>;
		};

		/* ipa - inbound entry from mss */
		smp2p_ipa_1_in: qcom,smp2p-ipa-1-in {
			qcom,entry-name = "ipa";
			interrupt-controller;
			#interrupt-cells = <2>;
		};
	};

	qcom,smp2p-wpss {
		compatible = "qcom,smp2p";
		qcom,smem = <617>, <616>;
		interrupt-parent = <&ipcc_mproc>;
		interrupts = <IPCC_CLIENT_WPSS IPCC_MPROC_SIGNAL_SMP2P
			      IRQ_TYPE_EDGE_RISING>;
		mboxes = <&ipcc_mproc IPCC_CLIENT_WPSS IPCC_MPROC_SIGNAL_SMP2P>;
		qcom,local-pid = <0>;
		qcom,remote-pid = <13>;

		wpss_smp2p_out: master-kernel {
			qcom,entry-name = "master-kernel";
			#qcom,smem-state-cells = <1>;
		};

		wpss_smp2p_in: slave-kernel {
			qcom,entry-name = "slave-kernel";
			interrupt-controller;
			#interrupt-cells = <2>;
		};

		smp2p_wlan_1_in: qcom,smp2p-wlan-1-in {
			qcom,entry-name = "wlan";
			interrupt-controller;
			#interrupt-cells = <2>;
		};

		smp2p_wlan_1_out: qcom,smp2p-wlan-1-out {
			qcom,entry-name = "wlan";
			#qcom,smem-state-cells = <1>;
		};
	};

	qcom,glink {
		compatible = "qcom,glink";
	};

	qcom,glinkpkt {
		compatible = "qcom,glinkpkt";

		qcom,glinkpkt-at-mdm0 {
			qcom,glinkpkt-edge = "mpss";
			qcom,glinkpkt-ch-name = "DS";
			qcom,glinkpkt-dev-name = "at_mdm0";
		};

		qcom,glinkpkt-apr-apps2 {
			qcom,glinkpkt-edge = "adsp";
			qcom,glinkpkt-ch-name = "apr_apps2";
			qcom,glinkpkt-dev-name = "apr_apps2";
		};

		qcom,glinkpkt-data40-cntl {
			qcom,glinkpkt-edge = "mpss";
			qcom,glinkpkt-ch-name = "DATA40_CNTL";
			qcom,glinkpkt-dev-name = "smdcntl8";
		};

		qcom,glinkpkt-data1 {
			qcom,glinkpkt-edge = "mpss";
			qcom,glinkpkt-ch-name = "DATA1";
			qcom,glinkpkt-dev-name = "smd7";
		};

		qcom,glinkpkt-data4 {
			qcom,glinkpkt-edge = "mpss";
			qcom,glinkpkt-ch-name = "DATA4";
			qcom,glinkpkt-dev-name = "smd8";
		};

		qcom,glinkpkt-data11 {
			qcom,glinkpkt-edge = "mpss";
			qcom,glinkpkt-ch-name = "DATA11";
			qcom,glinkpkt-dev-name = "smd11";
		};
	};

	wpss_pas: remoteproc-wpss@8a00000 {
		compatible = "qcom,yupik-wpss-pas";

		clocks = <&rpmhcc RPMH_CXO_CLK>;
		clock-names = "xo";

		cx-supply = <&VDD_CX_LEVEL>;
		cx-uV-uA = <RPMH_REGULATOR_LEVEL_TURBO 100000>;
		mx-supply = <&VDD_MX_LEVEL>;
		mx-uV-uA = <RPMH_REGULATOR_LEVEL_TURBO 100000>;
		reg-names = "cx","mx";

		firmware-name = "qca6750/wpss.mdt";
		memory-region = <&pil_wpss_mem>;

		/* Inputs from wpss */
		interrupts-extended = <&intc GIC_SPI 587 IRQ_TYPE_EDGE_RISING>,
				<&wpss_smp2p_in 0 0>,
				<&wpss_smp2p_in 2 0>,
				<&wpss_smp2p_in 1 0>,
				<&wpss_smp2p_in 3 0>,
				<&wpss_smp2p_in 7 0>;

		interrupt-names = "wdog",
				"fatal",
				"handover",
				"ready",
				"stop-ack",
				"shutdown-ack";

		/* Outputs to wpss */
		qcom,smem-states = <&wpss_smp2p_out 0>;
		qcom,smem-state-names = "stop";

		qcom,qmp = <&aoss_qmp>;

		remoteproc_wpss_glink: glink-edge {
			qcom,remote-pid = <13>;
			transport = "smem";
			mboxes = <&ipcc_mproc IPCC_CLIENT_WPSS
				  IPCC_MPROC_SIGNAL_GLINK_QMP>;
			mbox-names = "wpss_smem";
			interrupt-parent = <&ipcc_mproc>;
			interrupts = <IPCC_CLIENT_WPSS
					  IPCC_MPROC_SIGNAL_GLINK_QMP
					  IRQ_TYPE_EDGE_RISING>;

			label = "wpss";
			qcom,glink-label = "wpss";

			qcom,wpss_qrtr {
				qcom,glink-channels = "IPCRTR";
				qcom,intents = <0x800  5
						0x2000 3
						0x4400 2>;
			};
		};
	};

	aoss_qmp: power-controller@c300000 {
		compatible = "qcom,aoss-qmp";
		reg = <0x0c300000 0x400>;
		interrupt-parent = <&ipcc_mproc>;
		interrupts = <IPCC_CLIENT_AOP
				IPCC_MPROC_SIGNAL_GLINK_QMP
				IRQ_TYPE_EDGE_RISING>;
		mboxes = <&ipcc_mproc IPCC_CLIENT_AOP
			IPCC_MPROC_SIGNAL_GLINK_QMP>;

		#clock-cells = <0>;
		#power-domain-cells = <1>;
	};

	qmp_aop: qcom,qmp-aop {
		compatible = "qcom,qmp-mbox";
		qcom,qmp = <&aoss_qmp>;
		label = "aop";
		#mbox-cells = <1>;
		qcom,early-boot;
		priority = <0>;
		mbox-desc-offset = <0x0>;
	};

	aop-msg-client {
		compatible = "qcom,debugfs-qmp-client";
		mboxes = <&qmp_aop 0>;
		mbox-names = "aop";
	};

	qcom-secure-buffer {
		compatible = "qcom,secure-buffer";
		qcom,vmid-cp-camera-preview-ro;
	};

	qcom-mem-buf {
		compatible = "qcom,mem-buf";
		qcom,mem-buf-capabilities = "supplier";
		qcom,vmid = <3>;
	};

	sdhc1_opp_table: sdhc1-opp-table {
		compatible = "operating-points-v2";

		opp-100000000 {
			opp-hz = /bits/ 64 <100000000>;
			opp-peak-kBps = <250000 133320>;
			opp-avg-kBps = <104000 0>;
		};

		opp-384000000 {
			opp-hz = /bits/ 64 <384000000>;
			opp-peak-kBps = <800000 300000>;
			opp-avg-kBps = <400000 0>;
		};
	};

	sdhc_1: sdhci@7C4000 {
		compatible = "qcom,sdhci-msm-v5";
		reg = <0x007C4000 0x1000>, <0x007C5000 0x1000>,
		      <0x007c8000 0x8000>, <0x7d0000 0x9000>;
		reg-names = "hc", "cqhci", "cqhci_ice", "cqhci_ice_hwkm";

		iommus = <&apps_smmu 0xc0 0x0>;
		dma-coherent;
		qcom,iommu-dma = "fastmap";
		qcom,iommu-geometry = <0x40000000 0x20000000>;

		interrupts = <GIC_SPI 652 IRQ_TYPE_LEVEL_HIGH>,
				<GIC_SPI 656 IRQ_TYPE_LEVEL_HIGH>;
		interrupt-names = "hc_irq", "pwr_irq";

		clocks = <&gcc GCC_SDCC1_APPS_CLK>,
			<&gcc GCC_SDCC1_AHB_CLK>,
			<&gcc GCC_SDCC1_ICE_CORE_CLK>;
		clock-names = "core", "iface", "ice_core";

		qcom,ice-clk-rates = <300000000 100000000>;

		interconnects = <&aggre1_noc MASTER_SDCC_1 &mc_virt SLAVE_EBI1>,
			<&gem_noc MASTER_APPSS_PROC &cnoc2 SLAVE_SDCC_1>;
		interconnect-names = "sdhc-ddr","cpu-sdhc";

		operating-points-v2 = <&sdhc1_opp_table>;

		/* DLL HSR settings. Refer go/hsr - <Target> DLL settings */
		qcom,dll-hsr-list = <0x000f642c 0x0 0x0 0x2C010800 0x80040868>;

		mmc-ddr-1_8v;
		mmc-hs200-1_8v;
		mmc-hs400-1_8v;
		mmc-hs400-enhanced-strobe;

		cap-mmc-hw-reset;

		bus-width = <8>;
		non-removable;
		supports-cqe;

		boot_device_type = <0x1>;
		nvmem-cells = <&boot_config>;
		nvmem-cell-names = "boot_conf";

		qcom,scaling-lower-bus-speed-mode = "DDR52";

		/* Add dt entry for gcc hw reset */
		resets = <&gcc GCC_SDCC1_BCR>;
		reset-names = "core_reset";

		status = "disabled";

		qos0 {
			mask = <0x0f>;
			vote = <61>;
		};

		qos1 {
			mask = <0xf0>;
			vote = <67>;
		};
	};

	sdhc2_opp_table: sdhc2-opp-table {
		compatible = "operating-points-v2";

		opp-100000000 {
			opp-hz = /bits/ 64 <100000000>;
			opp-peak-kBps = <250000 133320>;
			opp-avg-kBps = <50000 0>;
		};

		opp-202000000 {
			opp-hz = /bits/ 64 <202000000>;
			opp-peak-kBps = <800000 300000>;
			opp-avg-kBps = <104000 0>;
		};
	};

	sdhc_2: sdhci@8804000 {
		compatible = "qcom,sdhci-msm-v5";
		reg = <0x08804000 0x1000>;
		reg-names = "hc_mem";

		iommus = <&apps_smmu 0x100 0x0>;
		dma-coherent;
		qcom,iommu-dma = "fastmap";

		interrupts = <GIC_SPI 207 IRQ_TYPE_LEVEL_HIGH>,
				<GIC_SPI 223 IRQ_TYPE_LEVEL_HIGH>;
		interrupt-names = "hc_irq", "pwr_irq";

		clocks = <&gcc GCC_SDCC2_APPS_CLK>, <&gcc GCC_SDCC2_AHB_CLK>;
		clock-names = "core", "iface";

		bus-width = <4>;

		interconnects = <&aggre1_noc MASTER_SDCC_2 &mc_virt SLAVE_EBI1>,
			<&gem_noc MASTER_APPSS_PROC &cnoc2 SLAVE_SDCC_2>;
		interconnect-names = "sdhc-ddr","cpu-sdhc";

		operating-points-v2 = <&sdhc2_opp_table>;
		/* DLL HSR settings. Refer go/hsr - <Target> DLL settings */
		qcom,dll-hsr-list = <0x0007642c 0x0 0x10 0x2C010800 0x80040868>;

		status = "disabled";

		qos0 {
			mask = <0x0f>;
			vote = <61>;
		};

		qos1 {
			mask = <0xf0>;
			vote = <67>;
		};
	};

	qcom,trustedvm@d0800000 {
		status = "ok";
		qcom,pas-id = <28>;
		qcom,firmware-name = "trustedvm";
		memory-region = <&pil_trustedvm_mem>;
	};

	qcom,guestvm_loader {
		image_to_be_loaded = "trustedvm";
	};

	qcom,svm_neuron_block {
		compatible = "qcom,neuron-service";
		#address-cells = <1>;
		#size-cells = <0>;
		protocol {
			compatible = "qcom,neuron-protocol-block";
			processes = "server";
		};

		application {
			compatible = "qcom,neuron-block-server";
		};

		channel@0 {
			compatible = "qcom,neuron-channel-haven-shmem";
			reg = <0>;
			class = "message-queue";
			direction = "receive";
			max-size = <0 65536>;
			shared-buffer = <&chan0_shbuf>;
			qcom,primary;
			haven-label = <1>;
			peer-name = <2>;
		};

		channel@1 {
			compatible = "qcom,neuron-channel-haven-shmem";
			reg = <1>;
			class = "message-queue";
			direction = "send";
			max-size = <0 65536>;
			shared-buffer = <&chan1_shbuf>;
			qcom,primary;
			haven-label = <2>;
			peer-name = <2>;
		};
	};

	qrtr-haven {
		compatible = "qcom,qrtr-haven";
		qcom,master;
		haven-label = <3>;
		peer-name = <2>;
		shared-buffer = <&qrtr_shbuf>;
	};

	modem_pas: remoteproc-mss@4080000 {
		compatible = "qcom,yupik-modem-pas";
		reg = <0x4080000 0x100>;

		cx-supply = <&VDD_CX_LEVEL>;
		cx-uV-uA = <RPMH_REGULATOR_LEVEL_TURBO 100000>;
		mx-supply = <&VDD_MODEM_LEVEL>;
		mx-uV-uA = <RPMH_REGULATOR_LEVEL_TURBO 100000>;
		reg-names = "cx", "mx";
		clocks = <&rpmhcc RPMH_CXO_CLK>;
		clock-names = "xo";

		memory-region = <&pil_mpss_mem>;
		firmware-name = "modem.mdt";

		qcom,qmp = <&aoss_qmp>;

		interconnects = <&mc_virt MASTER_LLCC &mc_virt SLAVE_EBI1>,
				<&aggre2_noc MASTER_CRYPTO &mc_virt SLAVE_EBI1>;
		interconnect-names = "rproc_ddr", "crypto_ddr";

		/* Inputs from mss */
		interrupts-extended = <&intc GIC_SPI 264 IRQ_TYPE_EDGE_RISING>,
				<&modem_smp2p_in 0 0>,
				<&modem_smp2p_in 2 0>,
				<&modem_smp2p_in 1 0>,
				<&modem_smp2p_in 3 0>,
				<&modem_smp2p_in 7 0>;

		interrupt-names = "wdog",
				"fatal",
				"handover",
				"ready",
				"stop-ack",
				"shutdown-ack";

		/* Outputs to mss */
		qcom,smem-states = <&modem_smp2p_out 0>;
		qcom,smem-state-names = "stop";

		glink-edge {
			qcom,remote-pid = <1>;
			transport = "smem";
			mboxes = <&ipcc_mproc IPCC_CLIENT_MPSS
				  IPCC_MPROC_SIGNAL_GLINK_QMP>;
			mbox-names = "mpss_smem";
			interrupt-parent = <&ipcc_mproc>;
			interrupts = <IPCC_CLIENT_MPSS
				      IPCC_MPROC_SIGNAL_GLINK_QMP
				      IRQ_TYPE_EDGE_RISING>;

			label = "modem";
			qcom,glink-label = "mpss";

			qcom,modem_qrtr {
				qcom,glink-channels = "IPCRTR";
				qcom,low-latency;
				qcom,intents = <0x800  5
						0x2000 3
						0x4400 2>;
			};

			qcom,modem_ds {
				qcom,glink-channels = "DS";
				qcom,intents = <0x4000 0x2>;
			};

		};
	};

	adsp_pas: remoteproc-adsp@3700000 {
		compatible = "qcom,yupik-adsp-pas";
		reg = <0x3700000 0x00100>;

		cx-supply = <&VDD_LPI_CX_LEVEL>;
		cx-uV-uA = <RPMH_REGULATOR_LEVEL_TURBO 0>;
		mx-supply = <&VDD_LPI_MX_LEVEL>;
		mx-uV-uA = <RPMH_REGULATOR_LEVEL_TURBO 0>;
		reg-names = "cx","mx";

		clocks = <&rpmhcc RPMH_CXO_CLK>;
		clock-names = "xo";

		firmware-name = "adsp.mdt";
		memory-region = <&pil_adsp_mem>;

		qcom,qmp = <&aoss_qmp>;

		interconnects = <&mc_virt MASTER_LLCC &mc_virt SLAVE_EBI1>,
				<&aggre2_noc MASTER_CRYPTO &mc_virt SLAVE_EBI1>;
		interconnect-names = "rproc_ddr", "crypto_ddr";

		/* Inputs from lpass */
		interrupts-extended = <&pdc 6 IRQ_TYPE_EDGE_RISING>,
				<&adsp_smp2p_in 0 0>,
				<&adsp_smp2p_in 2 0>,
				<&adsp_smp2p_in 1 0>,
				<&adsp_smp2p_in 3 0>,
				<&adsp_smp2p_in 7 0>;

		interrupt-names = "wdog",
				"fatal",
				"handover",
				"ready",
				"stop-ack",
				"shutdown-ack";

		/* Outputs to lpass */
		qcom,smem-states = <&adsp_smp2p_out 0>;
		qcom,smem-state-names = "stop";

		remoteproc_adsp_glink: glink-edge {
			qcom,remote-pid = <2>;
			transport = "smem";
			mboxes = <&ipcc_mproc IPCC_CLIENT_LPASS
				  IPCC_MPROC_SIGNAL_GLINK_QMP>;
			mbox-names = "adsp_smem";
			interrupt-parent = <&ipcc_mproc>;
			interrupts = <IPCC_CLIENT_LPASS
					  IPCC_MPROC_SIGNAL_GLINK_QMP
					  IRQ_TYPE_EDGE_RISING>;

			label = "adsp";
			qcom,glink-label = "lpass";

			qcom,adsp_qrtr {
				qcom,glink-channels = "IPCRTR";
				qcom,intents = <0x800  5
						0x2000 3
						0x4400 2>;
				qcom,non-wake-svc = <0x51
						0x190>;

			};

			qcom,pmic_glink_rpmsg {
				qcom,glink-channels = "PMIC_RTR_ADSP_APPS";
			};

			qcom,pmic_glink_log_rpmsg {
				qcom,glink-channels = "PMIC_LOGS_ADSP_APPS";
				qcom,intents = <0x800 5
						0xc00 3>;
			};
		};

	};

	cdsp_pas: remoteproc-cdsp@a300000 {
		compatible = "qcom,yupik-cdsp-pas";
		reg = <0xa300000 0x100000>;

		cx-supply = <&VDD_CX_LEVEL>;
		cx-uV-uA = <RPMH_REGULATOR_LEVEL_TURBO 100000>;
		mx-supply = <&VDD_MX_LEVEL>;
		mx-uV-uA = <RPMH_REGULATOR_LEVEL_TURBO 100000>;
		reg-names = "cx","mx";

		clocks = <&rpmhcc RPMH_CXO_CLK>;
		clock-names = "xo";
		qcom,proxy-clock-names = "xo";

		firmware-name = "cdsp.mdt";
		memory-region = <&pil_cdsp_mem>;

		qcom,qmp = <&aoss_qmp>;

		interconnects = <&nsp_noc MASTER_CDSP_PROC &mc_virt SLAVE_EBI1>,
				<&aggre2_noc MASTER_CRYPTO &mc_virt SLAVE_EBI1>;
		interconnect-names = "rproc_ddr", "crypto_ddr";

		/* Inputs from turing */
		interrupts-extended = <&intc GIC_SPI 578 IRQ_TYPE_EDGE_RISING>,
				<&cdsp_smp2p_in 0 0>,
				<&cdsp_smp2p_in 2 0>,
				<&cdsp_smp2p_in 1 0>,
				<&cdsp_smp2p_in 3 0>,
				<&cdsp_smp2p_in 7 0>;

		interrupt-names = "wdog",
				"fatal",
				"handover",
				"ready",
				"stop-ack",
				"shutdown-ack";

		/* Outputs to turing */
		qcom,smem-states = <&cdsp_smp2p_out 0>;
		qcom,smem-state-names = "stop";

		remoteproc_cdsp_glink: glink-edge {
			qcom,remote-pid = <5>;
			transport = "smem";
			mboxes = <&ipcc_mproc IPCC_CLIENT_CDSP
				  IPCC_MPROC_SIGNAL_GLINK_QMP>;
			mbox-names = "dsps_smem";
			interrupt-parent = <&ipcc_mproc>;
			interrupts = <IPCC_CLIENT_CDSP
					  IPCC_MPROC_SIGNAL_GLINK_QMP
					  IRQ_TYPE_EDGE_RISING>;

			label = "cdsp";
			qcom,glink-label = "cdsp";

			qcom,cdsp_qrtr {
				qcom,glink-channels = "IPCRTR";
				qcom,intents = <0x800  5
						0x2000 3
						0x4400 2>;
			};

			qcom,msm_cdsprm_rpmsg {
				compatible = "qcom,msm-cdsprm-rpmsg";
				qcom,glink-channels = "cdsprmglink-apps-dsp";
				qcom,intents = <0x20 12>;

				msm_cdsp_rm: qcom,msm_cdsp_rm {
					compatible = "qcom,msm-cdsp-rm";
					qcom,qos-latency-us = <70>;
					qcom,qos-maxhold-ms = <20>;
				};
			};
		};
	};

	qcom,rmtfs_sharedmem@0 {
		compatible = "qcom,sharedmem-uio";
		reg = <0x0 0x280000>;
		reg-names = "rmtfs";
		qcom,client-id = <0x00000001>;
		qcom,vm-nav-path;
	};

	qfprom: qfprom@780000 {
		compatible = "qcom,qfprom";
		reg = <0x780000 0x7000>;
		#address-cells = <1>;
		#size-cells = <1>;
		read-only;
		ranges;

		gpu_speed_bin: gpu_speed_bin@1e9 {
			reg = <0x1e9 0x2>;
			bits = <5 8>;
		};

		gpu_gaming_bin: gpu_gaming_bin@1f5 {
			reg = <0x1f5 0x1>;
			bits = <5 1>;
		};

		gpu_model_bin: gpu_model_bin@1e9 {
			reg = <0x1e9 0x2>;
			bits = <5 8>;
		};

		tsens_chipinfo: tsens_chipinfo@4180 {
			reg = <0x4180 0x4>;
		};

		feat_conf_m7: feat_conf_m7@6020 {
			reg = <0x6020 0x4>;
		};

		feat_conf_m9: feat_conf_m9@6028 {
			reg = <0x6028 0x4>;
		};

		adsp_variant: adsp_variant@6020 {
			reg = <0x6022 0x1>;
			bits = <2 4>;
		};

		boot_config: boot_config@6070 {
			reg = <0x6070 0x4>;
		};
	};

	qfprom_sys: qfprom@0 {
		compatible = "qcom,qfprom-sys";

		nvmem-cells = <&feat_conf_m7>,
			      <&feat_conf_m9>;
		nvmem-cell-names = "feat_conf_m7",
				   "feat_conf_m9";
	};

	qcom,msm-cdsp-loader {
		compatible = "qcom,cdsp-loader";
		qcom,proc-img-to-load = "cdsp";
	};

	qcom,msm-adsprpc-mem {
		compatible = "qcom,msm-adsprpc-mem-region";
		memory-region = <&adsp_mem>;
		restrict-access;
	};

	qcom_ramoops {
		compatible = "qcom,ramoops";
		memory-region = <&ramoops_mem>;
		pmsg-size = <0x200000>;
		mem-type = <2>;
	};

	qcom,sps {
		compatible = "qcom,msm-sps-4k";
		qcom,pipe-attr-ee;
	};

};

#include "shima-gdsc.dtsi"
#include "yupik-pinctrl.dtsi"
#include "ipcc-test-yupik.dtsi"
#include "yupik-regulators.dtsi"
#include "yupik-pcie.dtsi"

&gcc_ufs_phy_gdsc {
	qcom,support-hw-trigger;
	status = "ok";
};

&gcc_usb30_prim_gdsc {
	status = "ok";
};

&hlos1_vote_mmnoc_mmu_tbu_hf0_gdsc {
	status = "ok";
};

&hlos1_vote_mmnoc_mmu_tbu_hf1_gdsc {
	status = "ok";
};

&hlos1_vote_mmnoc_mmu_tbu_sf0_gdsc {
	status = "ok";
};

&hlos1_vote_turing_mmu_tbu0_gdsc {
	status = "ok";
};

&hlos1_vote_turing_mmu_tbu1_gdsc {
	status = "ok";
};

&cam_cc_titan_top_gdsc {
	clocks = <&gcc GCC_CAMERA_AHB_CLK>;
	clock-names = "ahb_clk";
	parent-supply = <&VDD_CX_LEVEL>;
	reg = <0xad0c194 0x4>;
	status = "ok";
};

&cam_cc_bps_gdsc {
	clocks = <&gcc GCC_CAMERA_AHB_CLK>;
	clock-names = "ahb_clk";
	parent-supply = <&VDD_CX_LEVEL>;
	qcom,support-hw-trigger;
	status = "ok";
};

&cam_cc_ife_0_gdsc {
	clocks = <&gcc GCC_CAMERA_AHB_CLK>;
	clock-names = "ahb_clk";
	parent-supply = <&VDD_CX_LEVEL>;
	status = "ok";
};

&cam_cc_ife_1_gdsc {
	clocks = <&gcc GCC_CAMERA_AHB_CLK>;
	clock-names = "ahb_clk";
	parent-supply = <&VDD_CX_LEVEL>;
	status = "ok";
};

&cam_cc_ife_2_gdsc {
	clocks = <&gcc GCC_CAMERA_AHB_CLK>;
	clock-names = "ahb_clk";
	parent-supply = <&VDD_CX_LEVEL>;
	status = "ok";
};

&cam_cc_ipe_0_gdsc {
	clocks = <&gcc GCC_CAMERA_AHB_CLK>;
	clock-names = "ahb_clk";
	parent-supply = <&VDD_CX_LEVEL>;
	qcom,support-hw-trigger;
	status = "ok";
};

&disp_cc_mdss_core_gdsc {
	reg = <0xaf01004 0x4>;
	clocks = <&gcc GCC_DISP_AHB_CLK>;
	clock-names = "ahb_clk";
	parent-supply = <&VDD_CX_LEVEL>;
	qcom,support-hw-trigger;
	status = "ok";
};

&gpu_cx_gdsc {
	clocks = <&gcc GCC_GPU_CFG_AHB_CLK>;
	clock-names = "ahb_clk";
	parent-supply = <&VDD_CX_LEVEL>;
	qcom,retain-regs;
	status = "ok";
};

&gpu_gx_gdsc {
	clocks = <&gcc GCC_GPU_CFG_AHB_CLK>;
	clock-names = "ahb_clk";
	parent-supply = <&VDD_GFX_LEVEL>;
	qcom,retain-regs;
	qcom,skip-disable-before-sw-enable;
	status = "ok";
};

&video_cc_mvs0_gdsc {
	reg = <0xaaf3004 0x4>;
	clocks = <&gcc GCC_VIDEO_AHB_CLK>;
	clock-names = "ahb_clk";
	parent-supply = <&VDD_CX_LEVEL>;
	qcom,support-hw-trigger;
	status = "ok";
};

&video_cc_mvsc_gdsc {
	clocks = <&gcc GCC_VIDEO_AHB_CLK>;
	clock-names = "ahb_clk";
	parent-supply = <&VDD_CX_LEVEL>;
	status = "ok";
};

#include "yupik-usb.dtsi"
#include "yupik-debug.dtsi"
#include "yupik-dma-heaps.dtsi"
#include "msm-arm-smmu-yupik.dtsi"
#include "yupik-qupv3.dtsi"
#include "msm-rdbg.dtsi"
#include "yupik-thermal.dtsi"
#include "yupik-walt.dtsi"
#include "yupik-coresight.dtsi"

/* HS UART */
&qupv3_se7_4uart {
	status = "ok";
};

&qupv3_se1_i2c {
	status = "ok";
	nq@64 {
		compatible = "rtc6226";
		reg = <0x64>;
		fmint-gpio = <&tlmm 18 0>;
		vdd-supply = <&L11C>;
		rtc6226,vdd-supply-voltage = <2800000 2800000>;
		rtc6226,vdd-load = <15000>;
		vio-supply = <&L19B>;
		rtc6226,vio-supply-voltage = <1800000 1800000>;
	};

	fsa4480: fsa4480@42 {
		compatible = "qcom,fsa4480-i2c";
		reg = <0x42>;
	};
};
